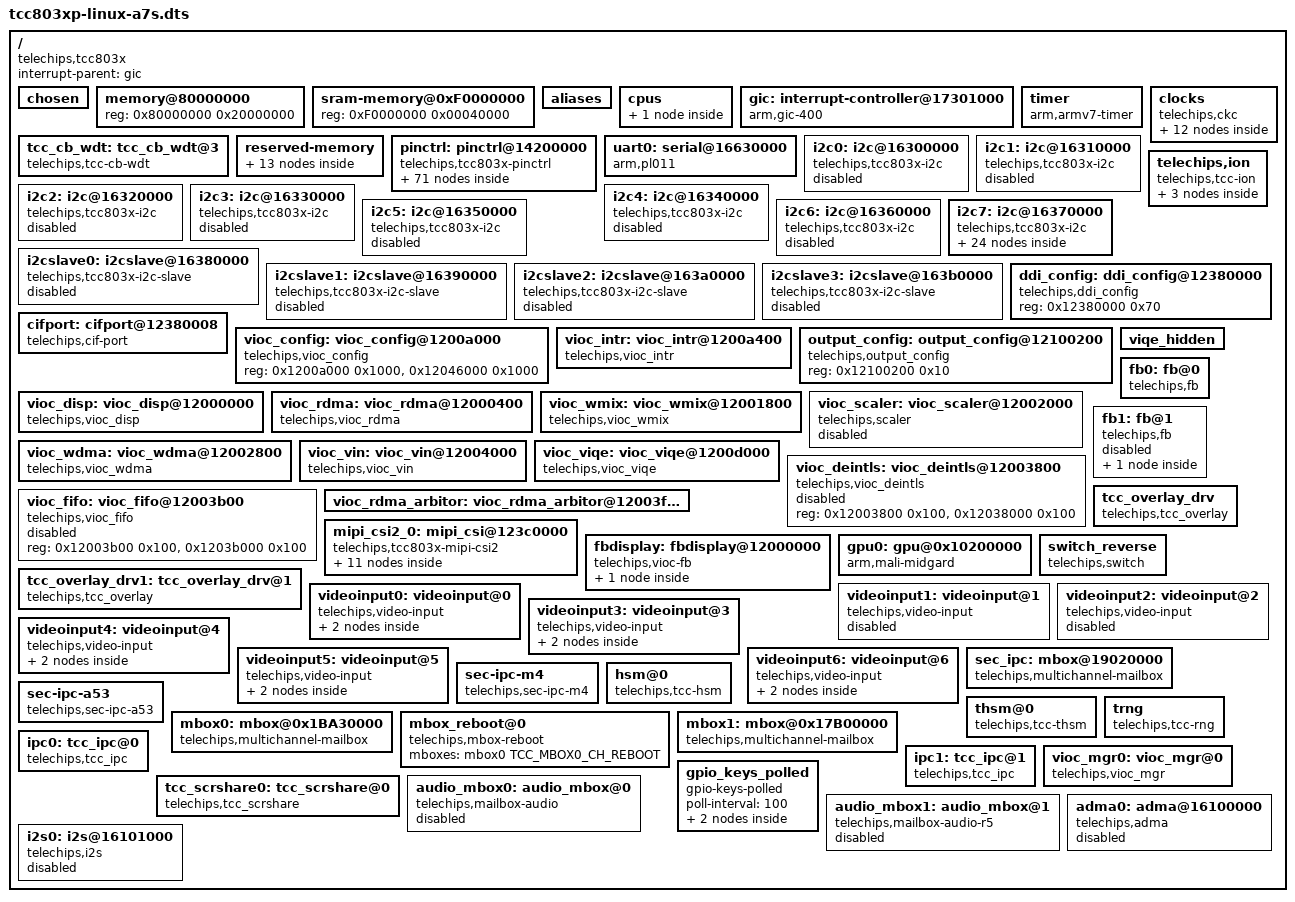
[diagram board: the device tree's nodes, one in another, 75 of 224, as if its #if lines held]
// SPDX-License-Identifier: (GPL-2.0-or-later OR MIT)
/*
 * Copyright (C) Telechips Inc.
 */

/dts-v1/;

#include <dt-bindings/interrupt-controller/arm-gic.h>
#include <dt-bindings/clock/telechips,tcc803x-clks.h>
#include <dt-bindings/display/tcc803x-vioc.h>
#include <dt-bindings/gpio/gpio.h>
#include <dt-bindings/mailbox/tcc803x_multi_mailbox/tcc_mbox_ch.h>
#include <dt-bindings/pmap/tcc803x/pmap-tcc803x-linux-ivi-subcore-a7s.h>

/ {
	compatible = "telechips,tcc803x";
	interrupt-parent = <&gic>;
	#address-cells = <1>;
	#size-cells = <1>;

	chosen {
		bootargs = "vmalloc=480M cgroup_disable=memory console=ttyAMA0,115200n8 initrd=0x87000000,22M quiet";
		stdout-path = &uart0;
	};

	memory@80000000 {
		#address-cells = <1>;
		#size-cells = <1>;
		device_type = "memory";
		reg = <0x80000000 0x20000000>;
	};

	sram-memory@0xF0000000 {
		reg = <0xF0000000 0x00040000>;
	};

	aliases {
		serial0 = &uart0;
		i2c0 = &i2c0;
		i2c1 = &i2c1;
		i2c2 = &i2c2;
		i2c3 = &i2c3;
		i2c4 = &i2c4;
		i2c5 = &i2c5;
		i2c6 = &i2c6;
		i2c7 = &i2c7;
		fb0 = &fb0;
		fb1 = &fb1;
		mipi-csi2-0 = &mipi_csi2_0;
		videoinput0 = &videoinput0;
		videoinput1 = &videoinput1;
		videoinput2 = &videoinput2;
		videoinput3 = &videoinput3;
		videoinput4 = &videoinput4;
		videoinput5 = &videoinput5;
		videoinput6 = &videoinput6;
		i2s0 = &i2s0;
		adma0 = &adma0;
#if defined(CONFIG_OVERLAY1)
		tcc-overlay-drv1 = &tcc_overlay_drv1;
#endif
	};

	cpus {
		#address-cells = <1>;
		#size-cells = <0>;

		cpu@0 {
			device_type = "cpu";
			compatible = "arm,cortex-a7";
			reg = <0x0>;
			clock-frequency = <1000000000>;
			operating-points = <
				/* kHz    uV */
				1000000  1100000
				925000   1050000
				850000   1000000
				775000   950000
				700000   900000
			>;
		};
	};

	gic: interrupt-controller@17301000 {
		compatible = "arm,gic-400";
		#interrupt-cells = <3>;
		#address-cells = <0>;
		interrupt-controller;
		reg = <0x17F01000 0x1000>,
		      <0x17F02000 0x1000>,
		      <0x17F04000 0x2000>,
		      <0x17F06000 0x2000>;
	};

	timer {
		compatible = "arm,armv7-timer";
		interrupts = <GIC_PPI 13 (GIC_CPU_MASK_SIMPLE(4) | IRQ_TYPE_LEVEL_LOW)>,
			     <GIC_PPI 14 (GIC_CPU_MASK_SIMPLE(4) | IRQ_TYPE_LEVEL_LOW)>,
			     <GIC_PPI 11 (GIC_CPU_MASK_SIMPLE(4) | IRQ_TYPE_LEVEL_LOW)>,
			     <GIC_PPI 10 (GIC_CPU_MASK_SIMPLE(4) | IRQ_TYPE_LEVEL_LOW)>;
	};

	tcc_cb_wdt: tcc_cb_wdt@3 {
		compatible = "telechips,tcc-cb-wdt";
		reg = <0x17040000 0x10000>, /* watchdog kick timer */
		    <0x17050000 0x10000>; /* real watchdog */
		clocks= <&clk_peri PERI_CB_WDT>;
		clock-frequency = <12000000>;
		interrupts = <GIC_SPI 121 0>;

		kick-interval = <5>;
		expire-timeout = <20>;

		status = "okay";
	};

	reserved-memory {
		#address-cells = <1>;
		#size-cells = <1>;
		ranges;

		/*-----------------------------------------------------------
		 * Secure Area 1 (CPU R/W, VPU X, GPU R/W, VIOC R)
		 *-----------------------------------------------------------
		 */
		pmap_fb_video: fb_video {
			compatible = "telechips,pmap";
			telechips,pmap-name = "fb_video";
			alloc-ranges = <RESERVED_MEM_BASE RESERVED_MEM_SIZE>;
			size = <PMAP_SIZE_FB_VIDEO>;
			no-map;
		};

		pmap_fb1_video: fb1_video {
			compatible = "telechips,pmap";
			telechips,pmap-name = "fb1_video";
			alloc-ranges = <RESERVED_MEM_BASE RESERVED_MEM_SIZE>;
			size = <PMAP_SIZE_FB1_VIDEO>;
			no-map;
		};

		/*-----------------------------------------------------------
		 * Secure Area 4 (CPU X, VPU X, GPU R/W, VIOC R/W)
		 *-----------------------------------------------------------
		 */
		pmap_ump_reserved: ump_reserved {
			compatible = "telechips,pmap";
			telechips,pmap-name = "ump_reserved";
			alloc-ranges = <RESERVED_MEM_BASE RESERVED_MEM_SIZE>;
			// Max-Video-Resolution(Aligned_256KB(w*h*3/2))*12+1MB
			size = <PMAP_SIZE_UMP_RESERVED>;
		};

		pmap_ion_carveout_cam: ion_carveout_cam {
			compatible = "telechips,pmap";
			telechips,pmap-name = "ion_carveout_cam";
			alloc-ranges = <RESERVED_MEM_BASE RESERVED_MEM_SIZE>;
			size = <PMAP_SIZE_ION_CARVEOUT_CAM>; // 12MB
		};

		/*-----------------------------------------------------------
		 * Camera Memory
		 *-----------------------------------------------------------
		 */
		pmap_parking_gui: parking_gui {
			compatible = "telechips,pmap";
			telechips,pmap-name = "parking_gui";
			alloc-ranges = <CAMERA_MEM_BASE CAMERA_MEM_SIZE>;
			size = <PMAP_SIZE_CAMERA_PGL>;
			no-map;
		};

		pmap_rearcamera_viqe: rearcamera_viqe {
			compatible = "telechips,pmap";
			telechips,pmap-name = "rearcamera_viqe";
			alloc-ranges = <CAMERA_MEM_BASE CAMERA_MEM_SIZE>;
			size = <PMAP_SIZE_CAMERA_VIQE>;
			no-map;
		};

		pmap_rearcamera: rearcamera {
			compatible = "telechips,pmap";
			telechips,pmap-name = "rearcamera";
			alloc-ranges = <CAMERA_MEM_BASE CAMERA_MEM_SIZE>;
			size = <PMAP_SIZE_CAMERA_PREVIEW0>;
			// no-map;
		};

		pmap_rearcamera1: rearcamera1 {
			compatible = "telechips,pmap";
			telechips,pmap-name = "rearcamera1";
			alloc-ranges = <CAMERA_MEM_BASE CAMERA_MEM_SIZE>;
			size = <PMAP_SIZE_CAMERA_PREVIEW1>;
			// no-map;
		};

		pmap_rearcamera2: rearcamera2 {
			compatible = "telechips,pmap";
			telechips,pmap-name = "rearcamera2";
			alloc-ranges = <CAMERA_MEM_BASE CAMERA_MEM_SIZE>;
			size = <PMAP_SIZE_CAMERA_PREVIEW2>;
			// no-map;
		};

		pmap_rearcamera3: rearcamera3 {
			compatible = "telechips,pmap";
			telechips,pmap-name = "rearcamera3";
			alloc-ranges = <CAMERA_MEM_BASE CAMERA_MEM_SIZE>;
			size = <PMAP_SIZE_CAMERA_PREVIEW3>;
			// no-map;
		};

		pmap_rearcamera4: rearcamera4 {
			compatible = "telechips,pmap";
			telechips,pmap-name = "rearcamera4";
			alloc-ranges = <CAMERA_MEM_BASE CAMERA_MEM_SIZE>;
			size = <PMAP_SIZE_CAMERA_PREVIEW4>;
			// no-map;
		};

		pmap_rearcamera5: rearcamera5 {
			compatible = "telechips,pmap";
			telechips,pmap-name = "rearcamera5";
			alloc-ranges = <CAMERA_MEM_BASE CAMERA_MEM_SIZE>;
			size = <PMAP_SIZE_CAMERA_PREVIEW5>;
			// no-map;
		};

		pmap_rearcamera6: rearcamera6 {
			compatible = "telechips,pmap";
			telechips,pmap-name = "rearcamera6";
			alloc-ranges = <CAMERA_MEM_BASE CAMERA_MEM_SIZE>;
			size = <PMAP_SIZE_CAMERA_PREVIEW6>;
			// no-map;
		};
	};

	clocks {
		compatible = "telechips,ckc";
		#address-cells = <1>;
		#size-cells = <1>;
		reg = <0x14000000 0x0001A8	/* ckc */
		       0x14400000 0x000114	/* pmu */
		       0x13500000 0x000018	/* memory bus configutaion */
		       0x12380000 0x000008	/* display bus configutaion */
		       0x10010000 0x000008	/* graphic bus configutaion */
		       0x16051000 0x000018	/* io bus configutaion 0 */
		       0x16494400 0x000008	/* io bus configutaion 1 */
		       0x15100000 0x200000	/* video bus configutaion */
		       0x11DA0000 0x000008	/* hsio bus configutaion */
		       0x17000000 0x300000	/* cpu bus configuration */
		       0x10000000 0x000010	/* graphic 3d clk */
		       0x1A000000 0x000010	/* graphic 2d clk */
		       0x13540000 0x000010>;	/* memory phy clk */

		osc24m: oscillator {
			compatible = "fixed-clock";
			#clock-cells = <0>;
			clock-frequency = <24000000>;
			clock-output-names = "osc24m";
		};

		clk_pll: pll_clk {
			compatible = "telechips,clk-pll";
			#clock-cells = <1>;
			clocks = <&osc24m>;
			clock-output-names = "pll0", "pll1", "pll2", "pll3",
					     "pll4";
		};

		clk_ext0: clk_ext@0 {
			compatible = "fixed-clock";
			#clock-cells = <0>;
			clock-frequency = <24000000>;
			clock-output-names = "clk_ext0";
		};

		clk_ext1: clk_ext@1 {
			compatible = "fixed-clock";
			#clock-cells = <0>;
			clock-frequency = <24000000>;
			clock-output-names = "clk_ext1";
		};

		clk_fbus: clk@14000008 {
			compatible = "telechips,clk-fbus";
			#clock-cells = <1>;
			clock-indices =
				<FBUS_CPU0>, <FBUS_CPU1>, <FBUS_CBUS>, <FBUS_CMBUS>,
				<FBUS_MEM>, <FBUS_VBUS>, <FBUS_HSIO>, <FBUS_SMU>,
				<FBUS_GPU>, <FBUS_DDI>, <FBUS_G2D>, <FBUS_IO>,
				<FBUS_CODA>, <FBUS_CHEVC>, <FBUS_BHEVC>,
				<FBUS_MEM_PHY>;
			clock-output-names =
				"fbus_cpu0", "fbus_cpu1", "fbus_cbus", "fbus_cmbus",
				"fbus_mem", "fbus_vbus", "fbus_hsio", "fbus_smu",
				"fbus_gpu", "fbus_ddi", "fbus_g2d", "fbus_io",
				"fbus_coda", "fbus_chevc", "fbus_bhevc",
				"fbus_mem_phy";
			telechips,clock-flags =
				<0>,	/* FBUS_CPU0 */
				<CLK_IGNORE_UNUSED>,	/* FBUS_CPU1 */
				<(CLK_SET_RATE_GATE | CLK_IGNORE_UNUSED)>,	/* FBUS_CBUS */
				<(CLK_SET_RATE_GATE | CLK_IGNORE_UNUSED)>,	/* FBUS_CMBUS */
				<(CLK_SET_RATE_GATE | CLK_IGNORE_UNUSED)>,	/* FBUS_MEM */
				<CLK_SET_RATE_GATE>,	/* FBUS_VBUS */
				<CLK_SET_RATE_GATE>,	/* FBUS_HSIO */
				<(CLK_SET_RATE_GATE | CLK_IGNORE_UNUSED)>,	/* FBUS_SMU */
				<0>,	/* FBUS_GPU */
				<CLK_SET_RATE_GATE>,	/* FBUS_DDI */
				<0>,	/* FBUS_G2D */
				<(CLK_SET_RATE_GATE | CLK_IS_CRITICAL)>,	/* FBUS_IO */
				<CLK_SET_RATE_GATE>,	/* FBUS_CODA */
				<CLK_SET_RATE_GATE>,	/* FBUS_CHEVC */
				<CLK_SET_RATE_GATE>,	/* FBUS_BHEVC */
				<0>;	/* FBUS_MEM_PHY */
		};

		clk_peri: clk@140000d0 {
			compatible = "telechips,clk-peri";
			#clock-cells = <1>;
			clock-indices =
				<PERI_TCX>, <PERI_TCT>, <PERI_TCZ>,
				<PERI_LCDTIMER>, <PERI_LCD0>, <PERI_LCD1>,
				<PERI_LCD2>, <PERI_CPUINTERFACE0>,
				<PERI_CPUINTERFACE1>, <PERI_HDMI_CORE>,
				<PERI_HDMI_AUDIO>, <PERI_HDMI_PCLK>,
				<PERI_HDMI_CEC>, <PERI_HDMI_HDCP14>,
				<PERI_HDMI_HDCP22>, <PERI_GMAC>,
				<PERI_PCIE_PCS>, <PERI_GMAC_PTP>,
				<PERI_PCIE_AUX>, <PERI_PCIE_REF_EXT>,
				<PERI_PCIE_APB>, <PERI_MIPI_CSI>, <PERI_RMT>,
				<PERI_SDMMC0>, <PERI_SDMMC1>, <PERI_SDMMC2>,
				<PERI_CEC1_CORE>, <PERI_MDAI0>, <PERI_MFLT0_DAI>,
				<PERI_MSPDIF0>, <PERI_SRCH0_CORE>,
				<PERI_SRCH0_FILTER>, <PERI_SRCH0_SPDIF>,
				<PERI_PDM>, <PERI_CEC1_SFR>, <PERI_TSADC>,
				<PERI_I2C0>, <PERI_I2C1>, <PERI_I2C2>, <PERI_I2C3>,
				<PERI_UART0>, <PERI_UART1>, <PERI_UART2>,
				<PERI_UART3>, <PERI_MDAI1>, <PERI_MFLT1_DAI>,
				<PERI_MSPDIF1>, <PERI_MDAI2>, <PERI_GPSB0>,
				<PERI_GPSB1>, <PERI_GPSB2>, <PERI_GPSBMS0>,
				<PERI_GPSBMS1>, <PERI_GPSBMS2>, <PERI_UART4>,
				<PERI_AUX0_INPUT>, <PERI_AUX1_INPUT>,
				<PERI_MFLT2_DAI>, <PERI_AUX0_OUTPUT>,
				<PERI_AUX1_OUTPUT>, <PERI_MSPDIF2>, <PERI_IC_TC>,
				<PERI_SRCH1_CORE>, <PERI_SRCH1_FILTER>,
				<PERI_SRCH1_SPDIF>, <PERI_SRCH2_CORE>,
				<PERI_SRCH2_FILTER>, <PERI_SRCH2_SPDIF>,
				<PERI_SRCH3_CORE>, <PERI_SRCH3_FILTER>,
				<PERI_SRCH3_SPDIF>, <PERI_TSRX0>, <PERI_TSRX1>,
				<PERI_TSRX2>, <PERI_TSRX3>, <PERI_TSRX4>,
				<PERI_TSRX5>, <PERI_TSRX6>, <PERI_TSRX7>,
				<PERI_TSRX8>, <PERI_CB_WDT>, <PERI_LVDS_PHY>,
				<PERI_OUT0>, <PERI_OUT1>, <PERI_OUT2>, <PERI_OUT3>,
				<PERI_OUT4>, <PERI_OUT5>;
			clock-output-names =
				"peri_tcx", "peri_tct", "peri_tcz",
				"peri_lcdtimer", "peri_lcd0", "peri_lcd1",
				"peri_lcd2", "peri_cpuinterface0",
				"peri_cpuinterface1", "peri_hdmi_core",
				"peri_hdmi_audio", "peri_hdmi_pclk",
				"peri_hdmi_cec", "peri_hdmi_hdcp14",
				"peri_hdmi_hdcp22", "peri_gmac",
				"peri_pcie_pcs", "peri_gmac_ptp",
				"peri_pcie_aux", "peri_pcie_ref_ext",
				"peri_pcie_apb", "peri_mipi_csi", "peri_rmt",
				"peri_sdmmc0", "peri_sdmmc1", "peri_sdmmc2",
				"peri_cec1_core", "peri_mdai0", "peri_mflt0_dai",
				"peri_mspdif0", "peri_srch0_core",
				"peri_srch0_filter", "peri_srch0_spdif",
				"peri_pdm", "peri_cec1_sfr", "peri_tsadc",
				"peri_i2c0", "peri_i2c1", "peri_i2c2", "peri_i2c3",
				"peri_uart0", "peri_uart1", "peri_uart2",
				"peri_uart3", "peri_mdai1", "peri_mflt1_dai",
				"peri_mspdif1", "peri_mdai2", "peri_gpsb0",
				"peri_gpsb1", "peri_gpsb2", "peri_gpsbms0",
				"peri_gpsbms1", "peri_gpsbms2", "peri_uart4",
				"peri_aux0_input", "peri_aux1_input",
				"peri_mflt2_dai", "peri_aux0_output",
				"peri_aux1_output", "peri_mspdif2", "peri_ic_tc",
				"peri_srch1_core", "peri_srch1_filter",
				"peri_srch1_spdif", "peri_srch2_core",
				"peri_srch2_filter", "peri_srch2_spdif",
				"peri_srch3_core", "peri_srch3_filter",
				"peri_srch3_spdif", "peri_tsrx0", "peri_tsrx1",
				"peri_tsrx2", "peri_tsrx3", "peri_tsrx4",
				"peri_tsrx5", "peri_tsrx6", "peri_tsrx7",
				"peri_tsrx8", "peri_cb_wdt", "peri_lvds_phy",
				"peri_out0", "peri_out1", "peri_out2", "peri_out3",
				"peri_out4", "peri_out5";
			telechips,clock-flags =
				<CLK_IGNORE_UNUSED>,	/* PERI_TCX */
				<CLK_IGNORE_UNUSED>,	/* PERI_TCT */
				<CLK_IGNORE_UNUSED>,	/* PERI_TCZ */
				<CLK_IGNORE_UNUSED>,	/* PERI_LCDTIMER */
				<CLK_IGNORE_UNUSED>,	/* PERI_LCD0 */
				<CLK_IGNORE_UNUSED>,	/* PERI_LCD1 */
				<CLK_IGNORE_UNUSED>,	/* PERI_LCD2 */
				<CLK_IGNORE_UNUSED>,	/* PERI_CPUINTERFACE0 */
				<CLK_IGNORE_UNUSED>,	/* PERI_CPUINTERFACE1 */
				<CLK_IGNORE_UNUSED>,	/* PERI_HDMI_CORE */
				<CLK_IGNORE_UNUSED>,	/* PERI_HDMI_AUDIO */
				<CLK_IGNORE_UNUSED>,	/* PERI_HDMI_PCLK */
				<CLK_IGNORE_UNUSED>,	/* PERI_HDMI_CEC */
				<CLK_IGNORE_UNUSED>,	/* PERI_HDMI_HDCP14 */
				<CLK_IGNORE_UNUSED>,	/* PERI_HDMI_HDCP22 */
				<CLK_IGNORE_UNUSED>,	/* PERI_GMAC */
				<CLK_IGNORE_UNUSED>,	/* PERI_PCIE_PCS */
				<CLK_IGNORE_UNUSED>,	/* PERI_GMAC_PTP */
				<CLK_IGNORE_UNUSED>,	/* PERI_PCIE_AUX */
				<CLK_IGNORE_UNUSED>,	/* PERI_PCIE_REF_EXT */
				<CLK_IGNORE_UNUSED>,	/* PERI_PCIE_APB */
				<CLK_IGNORE_UNUSED>,	/* PERI_MIPI_CSI */
				<CLK_IGNORE_UNUSED>,	/* PERI_RMT */
				<CLK_IGNORE_UNUSED>,	/* PERI_SDMMC0 */
				<CLK_IGNORE_UNUSED>,	/* PERI_SDMMC1 */
				<CLK_IGNORE_UNUSED>,	/* PERI_SDMMC2 */
				<CLK_IGNORE_UNUSED>,	/* PERI_CEC1_CORE */
				<CLK_IGNORE_UNUSED>,	/* PERI_MDAI0 */
				<CLK_IGNORE_UNUSED>,	/* PERI_MFLT0_DAI */
				<CLK_IGNORE_UNUSED>,	/* PERI_MSPDIF0 */
				<CLK_IGNORE_UNUSED>,	/* PERI_SRCH0_CORE */
				<CLK_IGNORE_UNUSED>,	/* PERI_SRCH0_FILTER */
				<CLK_IGNORE_UNUSED>,	/* PERI_SRCH0_SPDIF */
				<CLK_IGNORE_UNUSED>,	/* PERI_PDM */
				<CLK_IGNORE_UNUSED>,	/* PERI_CEC1_SFR */
				<CLK_IGNORE_UNUSED>,	/* PERI_TSADC */
				<CLK_IGNORE_UNUSED>,	/* PERI_I2C0 */
				<CLK_IGNORE_UNUSED>,	/* PERI_I2C1 */
				<CLK_IGNORE_UNUSED>,	/* PERI_I2C2 */
				<CLK_IGNORE_UNUSED>,	/* PERI_I2C3 */
				<CLK_IGNORE_UNUSED>,	/* PERI_UART0 */
				<CLK_IGNORE_UNUSED>,	/* PERI_UART1 */
				<CLK_IGNORE_UNUSED>,	/* PERI_UART2 */
				<CLK_IGNORE_UNUSED>,	/* PERI_UART3 */
				<CLK_IGNORE_UNUSED>,	/* PERI_MDAI1 */
				<CLK_IGNORE_UNUSED>,	/* PERI_MFLT1_DAI */
				<CLK_IGNORE_UNUSED>,	/* PERI_MSPDIF1 */
				<CLK_IGNORE_UNUSED>,	/* PERI_MDAI2 */
				<CLK_IGNORE_UNUSED>,	/* PERI_GPSB0 */
				<CLK_IGNORE_UNUSED>,	/* PERI_GPSB1 */
				<CLK_IGNORE_UNUSED>,	/* PERI_GPSB2 */
				<CLK_IGNORE_UNUSED>,	/* PERI_GPSBMS0 */
				<CLK_IGNORE_UNUSED>,	/* PERI_GPSBMS1 */
				<CLK_IGNORE_UNUSED>,	/* PERI_GPSBMS2 */
				<CLK_IGNORE_UNUSED>,	/* PERI_UART4 */
				<CLK_IGNORE_UNUSED>,	/* PERI_AUX0_INPUT */
				<CLK_IGNORE_UNUSED>,	/* PERI_AUX1_INPUT */
				<CLK_IGNORE_UNUSED>,	/* PERI_MFLT2_DAI */
				<CLK_IGNORE_UNUSED>,	/* PERI_AUX0_OUTPUT */
				<CLK_IGNORE_UNUSED>,	/* PERI_AUX1_OUTPUT */
				<CLK_IGNORE_UNUSED>,	/* PERI_MSPDIF2 */
				<CLK_IGNORE_UNUSED>,	/* PERI_IC_TC */
				<CLK_IGNORE_UNUSED>,	/* PERI_SRCH1_CORE */
				<CLK_IGNORE_UNUSED>,	/* PERI_SRCH1_FILTER */
				<CLK_IGNORE_UNUSED>,	/* PERI_SRCH1_SPDIF */
				<CLK_IGNORE_UNUSED>,	/* PERI_SRCH2_CORE */
				<CLK_IGNORE_UNUSED>,	/* PERI_SRCH2_FILTER */
				<CLK_IGNORE_UNUSED>,	/* PERI_SRCH2_SPDIF */
				<CLK_IGNORE_UNUSED>,	/* PERI_SRCH3_CORE */
				<CLK_IGNORE_UNUSED>,	/* PERI_SRCH3_FILTER */
				<CLK_IGNORE_UNUSED>,	/* PERI_SRCH3_SPDIF */
				<CLK_IGNORE_UNUSED>,	/* PERI_TSRX0 */
				<CLK_IGNORE_UNUSED>,	/* PERI_TSRX1 */
				<CLK_IGNORE_UNUSED>,	/* PERI_TSRX2 */
				<CLK_IGNORE_UNUSED>,	/* PERI_TSRX3 */
				<CLK_IGNORE_UNUSED>,	/* PERI_TSRX4 */
				<CLK_IGNORE_UNUSED>,	/* PERI_TSRX5 */
				<CLK_IGNORE_UNUSED>,	/* PERI_TSRX6 */
				<CLK_IGNORE_UNUSED>,	/* PERI_TSRX7 */
				<CLK_IGNORE_UNUSED>,	/* PERI_TSRX8 */
				<CLK_IGNORE_UNUSED>,	/* PERI_CB_WDT */
				<CLK_IGNORE_UNUSED>,	/* PERI_LVDS_PHY */
				<CLK_IGNORE_UNUSED>,	/* PERI_OUT0 */
				<CLK_IGNORE_UNUSED>,	/* PERI_OUT1 */
				<CLK_IGNORE_UNUSED>,	/* PERI_OUT2 */
				<CLK_IGNORE_UNUSED>,	/* PERI_OUT3 */
				<CLK_IGNORE_UNUSED>,	/* PERI_OUT4 */
				<CLK_IGNORE_UNUSED>;	/* PERI_OUT5 */
		};

		clk_io: clk@16051000 {
			compatible = "telechips,clk-iobus";
			#clock-cells = <1>;
			clocks = <&clk_fbus FBUS_IO>;
			clock-indices =
				<IOBUS_ASRC_DMA>, <IOBUS_ASRC>, <IOBUS_IC_TC>,
				<IOBUS_CEC1>, <IOBUS_DMA0>, <IOBUS_DMA1>,
				<IOBUS_DMA2>, <IOBUS_DMA>, <IOBUS_PWM>,
				<IOBUS_I2C_S2>, <IOBUS_REMOCON>, <IOBUS_PRT>,
				<IOBUS_ADMA0>, <IOBUS_DAI0>, <IOBUS_SPDIF0>,
				<IOBUS_AUDIO0>, <IOBUS_SR_ADMA0>,
				<IOBUS_SR_DAI0>, <IOBUS_SR_SPDIF0>,
				<IOBUS_SR_AUDIO0>, <IOBUS_I2C_M0>,
				<IOBUS_I2C_M1>, <IOBUS_I2C_M2>, <IOBUS_I2C_M3>,
				<IOBUS_I2C_S0>, <IOBUS_I2C_S1>, <IOBUS_I2C0>,
				<IOBUS_I2C1>, <IOBUS_GPSB_2>, <IOBUS_GPSB0>,
				<IOBUS_GPSB1>, <IOBUS_GPSB2>, <IOBUS_GPSB3>,
				<IOBUS_GPSB4>, <IOBUS_GPSB5>, <IOBUS_GPSB>,
				<IOBUS_I2C_S3>, <IOBUS_I2C_M4>, <IOBUS_I2C_M5>,
				<IOBUS_I2C_M6>, <IOBUS_I2C_M7>, <IOBUS_UART0>,
				<IOBUS_UART1>, <IOBUS_UART2>, <IOBUS_UART3>,
				<IOBUS_UART4>, <IOBUS_SMARTCARD4>, <IOBUS_UDMA0>,
				<IOBUS_UDMA1>, <IOBUS_UDMA2>, <IOBUS_UDMA3>,
				<IOBUS_UART_SMARTCARD0>,
				<IOBUS_UART_SMARTCARD1>, <IOBUS_ADMA1>, <IOBUS_DAI1>,
				<IOBUS_SPDIF1>, <IOBUS_AUDIO1>, <IOBUS_ADMA2>,
				<IOBUS_DAI2>, <IOBUS_SPDIF2>, <IOBUS_AUDIO2>,
				<IOBUS_SR_ADMA1>, <IOBUS_SR_DAI1>,
				<IOBUS_SR_SPDIF1>, <IOBUS_SR_AUDIO1>,
				<IOBUS_SR_ADMA2>, <IOBUS_SR_DAI2>,
				<IOBUS_SR_SPDIF2>, <IOBUS_SR_AUDIO2>,
				<IOBUS_SR_ADMA3>, <IOBUS_SR_DAI3>,
				<IOBUS_SR_SPDIF3>, <IOBUS_SR_AUDIO3>, <IOBUS_GDMA1>,
				<IOBUS_CIPHER>, <IOBUS_SDMMC0>, <IOBUS_SDMMC1>,
				<IOBUS_SDMMC2>, <IOBUS_SDMMC>, <IOBUS_SMC>,
				<IOBUS_NFC>, <IOBUS_EDICFG>, <IOBUS_EDI>,
				<IOBUS_RTC>;
			clock-output-names =
				"iobus_asrc_dma", "iobus_asrc", "iobus_ic_tc",
				"iobus_cec1", "iobus_dma0", "iobus_dma1",
				"iobus_dma2", "iobus_dma", "iobus_pwm",
				"iobus_i2c_s2", "iobus_remocon", "iobus_prt",
				"iobus_adma0", "iobus_dai0", "iobus_spdif0",
				"iobus_audio0", "iobus_sr_adma0",
				"iobus_sr_dai0", "iobus_sr_spdif0",
				"iobus_sr_audio0", "iobus_i2c_m0",
				"iobus_i2c_m1", "iobus_i2c_m2", "iobus_i2c_m3",
				"iobus_i2c_s0", "iobus_i2c_s1", "iobus_i2c0",
				"iobus_i2c1", "iobus_gpsb_2", "iobus_gpsb0",
				"iobus_gpsb1", "iobus_gpsb2", "iobus_gpsb3",
				"iobus_gpsb4", "iobus_gpsb5", "iobus_gpsb",
				"iobus_i2c_s3", "iobus_i2c_m4", "iobus_i2c_m5",
				"iobus_i2c_m6", "iobus_i2c_m7", "iobus_uart0",
				"iobus_uart1", "iobus_uart2", "iobus_uart3",
				"iobus_uart4", "iobus_smartcard4", "iobus_udma0",
				"iobus_udma1", "iobus_udma2", "iobus_udma3",
				"iobus_uart_smartcard0",
				"iobus_uart_smartcard1", "iobus_adma1", "iobus_dai1",
				"iobus_spdif1", "iobus_audio1", "iobus_adma2",
				"iobus_dai2", "iobus_spdif2", "iobus_audio2",
				"iobus_sr_adma1", "iobus_sr_dai1",
				"iobus_sr_spdif1", "iobus_sr_audio1",
				"iobus_sr_adma2", "iobus_sr_dai2",
				"iobus_sr_spdif2", "iobus_sr_audio2",
				"iobus_sr_adma3", "iobus_sr_dai3",
				"iobus_sr_spdif3", "iobus_sr_audio3", "iobus_gdma1",
				"iobus_cipher", "iobus_sdmmc0", "iobus_sdmmc1",
				"iobus_sdmmc2", "iobus_sdmmc", "iobus_smc",
				"iobus_nfc", "iobus_edicfg", "iobus_edi",
				"iobus_rtc";
			telechips,clock-flags =
				<CLK_IGNORE_UNUSED>,	/* IOBUS_ASRC_DMA */
				<CLK_IGNORE_UNUSED>,	/* IOBUS_ASRC */
				<CLK_IGNORE_UNUSED>,	/* IOBUS_IC_TC */
				<CLK_IGNORE_UNUSED>,	/* IOBUS_CEC1 */
				<CLK_IGNORE_UNUSED>,	/* IOBUS_DMA0 */
				<CLK_IGNORE_UNUSED>,	/* IOBUS_DMA1 */
				<CLK_IGNORE_UNUSED>,	/* IOBUS_DMA2 */
				<CLK_IGNORE_UNUSED>,	/* IOBUS_DMA */
				<CLK_IGNORE_UNUSED>,	/* IOBUS_PWM */
				<CLK_IGNORE_UNUSED>,	/* IOBUS_I2C_S2 */
				<CLK_IGNORE_UNUSED>,	/* IOBUS_REMOCON */
				<CLK_IGNORE_UNUSED>,	/* IOBUS_PRT */
				<CLK_IGNORE_UNUSED>,	/* IOBUS_ADMA0 */
				<CLK_IGNORE_UNUSED>,	/* IOBUS_DAI0 */
				<CLK_IGNORE_UNUSED>,	/* IOBUS_SPDIF0 */
				<CLK_IGNORE_UNUSED>,	/* IOBUS_AUDIO0 */
				<CLK_IGNORE_UNUSED>,	/* IOBUS_SR_ADMA0 */
				<CLK_IGNORE_UNUSED>,	/* IOBUS_SR_DAI0 */
				<CLK_IGNORE_UNUSED>,	/* IOBUS_SR_SPDIF0 */
				<CLK_IGNORE_UNUSED>,	/* IOBUS_SR_AUDIO0 */
				<CLK_IGNORE_UNUSED>,	/* IOBUS_I2C_M0 */
				<CLK_IGNORE_UNUSED>,	/* IOBUS_I2C_M1 */
				<CLK_IGNORE_UNUSED>,	/* IOBUS_I2C_M2 */
				<CLK_IGNORE_UNUSED>,	/* IOBUS_I2C_M3 */
				<CLK_IGNORE_UNUSED>,	/* IOBUS_I2C_S0 */
				<CLK_IGNORE_UNUSED>,	/* IOBUS_I2C_S1 */
				<CLK_IGNORE_UNUSED>,	/* IOBUS_I2C0 */
				<CLK_IGNORE_UNUSED>,	/* IOBUS_I2C1 */
				<CLK_IGNORE_UNUSED>,	/* IOBUS_GPSB_2 */
				<CLK_IGNORE_UNUSED>,	/* IOBUS_GPSB0 */
				<CLK_IGNORE_UNUSED>,	/* IOBUS_GPSB1 */
				<CLK_IGNORE_UNUSED>,	/* IOBUS_GPSB2 */
				<CLK_IGNORE_UNUSED>,	/* IOBUS_GPSB3 */
				<CLK_IGNORE_UNUSED>,	/* IOBUS_GPSB4 */
				<CLK_IGNORE_UNUSED>,	/* IOBUS_GPSB5 */
				<CLK_IGNORE_UNUSED>,	/* IOBUS_GPSB */
				<CLK_IGNORE_UNUSED>,	/* IOBUS_I2C_S3 */
				<CLK_IGNORE_UNUSED>,	/* IOBUS_I2C_M4 */
				<CLK_IGNORE_UNUSED>,	/* IOBUS_I2C_M5 */
				<CLK_IGNORE_UNUSED>,	/* IOBUS_I2C_M6 */
				<CLK_IGNORE_UNUSED>,	/* IOBUS_I2C_M7 */
				<CLK_IGNORE_UNUSED>,	/* IOBUS_UART0 */
				<CLK_IGNORE_UNUSED>,	/* IOBUS_UART1 */
				<CLK_IGNORE_UNUSED>,	/* IOBUS_UART2 */
				<CLK_IGNORE_UNUSED>,	/* IOBUS_UART3 */
				<CLK_IGNORE_UNUSED>,	/* IOBUS_UART4 */
				<CLK_IGNORE_UNUSED>,	/* IOBUS_SMARTCARD4 */
				<CLK_IGNORE_UNUSED>,	/* IOBUS_UDMA0 */
				<CLK_IGNORE_UNUSED>,	/* IOBUS_UDMA1 */
				<CLK_IGNORE_UNUSED>,	/* IOBUS_UDMA2 */
				<CLK_IGNORE_UNUSED>,	/* IOBUS_UDMA3 */
				<CLK_IGNORE_UNUSED>,	/* IOBUS_UART_SMARTCARD0 */
				<CLK_IGNORE_UNUSED>,	/* IOBUS_UART_SMARTCARD1 */
				<CLK_IGNORE_UNUSED>,	/* IOBUS_ADMA1 */
				<CLK_IGNORE_UNUSED>,	/* IOBUS_DAI1 */
				<CLK_IGNORE_UNUSED>,	/* IOBUS_SPDIF1 */
				<CLK_IGNORE_UNUSED>,	/* IOBUS_AUDIO1 */
				<CLK_IGNORE_UNUSED>,	/* IOBUS_ADMA2 */
				<CLK_IGNORE_UNUSED>,	/* IOBUS_DAI2 */
				<CLK_IGNORE_UNUSED>,	/* IOBUS_SPDIF2 */
				<CLK_IGNORE_UNUSED>,	/* IOBUS_AUDIO2 */
				<CLK_IGNORE_UNUSED>,	/* IOBUS_SR_ADMA1 */
				<CLK_IGNORE_UNUSED>,	/* IOBUS_SR_DAI1 */
				<CLK_IGNORE_UNUSED>,	/* IOBUS_SR_SPDIF1 */
				<CLK_IGNORE_UNUSED>,	/* IOBUS_SR_AUDIO1 */
				<CLK_IGNORE_UNUSED>,	/* IOBUS_SR_ADMA2 */
				<CLK_IGNORE_UNUSED>,	/* IOBUS_SR_DAI2 */
				<CLK_IGNORE_UNUSED>,	/* IOBUS_SR_SPDIF2 */
				<CLK_IGNORE_UNUSED>,	/* IOBUS_SR_AUDIO2 */
				<CLK_IGNORE_UNUSED>,	/* IOBUS_SR_ADMA3 */
				<CLK_IGNORE_UNUSED>,	/* IOBUS_SR_DAI3 */
				<CLK_IGNORE_UNUSED>,	/* IOBUS_SR_SPDIF3 */
				<CLK_IGNORE_UNUSED>,	/* IOBUS_SR_AUDIO3 */
				<CLK_IGNORE_UNUSED>,	/* IOBUS_GDMA1 */
				<CLK_IGNORE_UNUSED>,	/* IOBUS_CIPHER */
				<CLK_IGNORE_UNUSED>,	/* IOBUS_SDMMC0 */
				<CLK_IGNORE_UNUSED>,	/* IOBUS_SDMMC1 */
				<CLK_IGNORE_UNUSED>,	/* IOBUS_SDMMC2 */
				<CLK_IGNORE_UNUSED>,	/* IOBUS_SDMMC */
				<CLK_IGNORE_UNUSED>,	/* IOBUS_SMC */
				<CLK_IGNORE_UNUSED>,	/* IOBUS_NFC */
				<CLK_IGNORE_UNUSED>,	/* IOBUS_EDICFG */
				<CLK_IGNORE_UNUSED>,	/* IOBUS_EDI */
				<CLK_IGNORE_UNUSED>;	/* IOBUS_RTC */
		};

		clk_hsio: clk@111a0000 {
			compatible = "telechips,clk-hsiobus";
			#clock-cells = <1>;
			clocks = <&clk_fbus FBUS_HSIO>;
			clock-indices =
				<HSIOBUS_GMAC>, <HSIOBUS_HSIC>, <HSIOBUS_USB20H>,
				<HSIOBUS_CIPHER>, <HSIOBUS_USB20DH>,
				<HSIOBUS_SECURE_WRAP>, <HSIOBUS_TRNG>;
			clock-output-names =
				"hsiobus_gmac", "hsiobus_hsic", "hsiobus_usb20h",
				"hsiobus_cipher", "hsiobus_usb20dh",
				"hsiobus_secure_wrap", "hsiobus_trng";
			telechips,clock-flags =
				<CLK_IGNORE_UNUSED>,	/* HSIOBUS_GMAC */
				<CLK_IGNORE_UNUSED>,	/* HSIOBUS_HSIC */
				<CLK_IGNORE_UNUSED>,	/* HSIOBUS_USB20H */
				<CLK_IGNORE_UNUSED>,	/* HSIOBUS_CIPHER */
				<CLK_IGNORE_UNUSED>,	/* HSIOBUS_USB20DH */
				<CLK_IGNORE_UNUSED>,	/* HSIOBUS_SECURE_WRAP */
				<CLK_IGNORE_UNUSED>;	/* HSIOBUS_TRNG */
		};
		clk_ddi: clk@12380000 {
			compatible = "telechips,clk-ddibus";
			#clock-cells = <1>;
			clocks = <&clk_fbus FBUS_DDI>;
			clock-indices =
				<DDIBUS_VIOC>, <DDIBUS_HDMI>, <DDIBUS_MIPI>,
				<DDIBUS_LVDS>;
			clock-output-names =
				"ddibus_vioc", "ddibus_hdmi", "ddibus_mipi",
				"ddibus_lvds";
			telechips,clock-flags =
				<CLK_IGNORE_UNUSED>,	/* DDIBUS_VIOC */
				<CLK_IGNORE_UNUSED>,	/* DDIBUS_HDMI */
				<CLK_IGNORE_UNUSED>,	/* DDIBUS_MIPI */
				<CLK_IGNORE_UNUSED>;	/* DDIBUS_LVDS */
		};

		clk_vpu: clk@15100000 {
			compatible = "telechips,clk-vpubus";
			#clock-cells = <1>;
			clocks = <&clk_fbus FBUS_VBUS>;
			clock-indices =
				<VIDEOBUS_JPEG>, <VIDEOBUS_CODA_BUS>,
				<VIDEOBUS_CODA_CORE>, <VIDEOBUS_HEVC_BUS>,
				<VIDEOBUS_HEVC_CORE>;
			clock-output-names =
				"videobus_jpeg", "videobus_coda_bus",
				"videobus_coda_core", "videobus_hevc_bus",
				"videobus_hevc_core";
			telechips,clock-flags =
				<0>,	/* VIDEOBUS_JPEG */
				<0>,	/* VIDEOBUS_CODA_BUS */
				<0>,	/* VIDEOBUS_CODA_CORE */
				<0>,	/* VIDEOBUS_HEVC_BUS */
				<0>;	/* VIDEOBUS_HEVC_CORE */
		};

		clk_isoip_top: clk@1440007c {
			compatible = "telechips,clk-isoip_top";
			#clock-cells = <1>;
			clock-indices =
				<ISOIP_TOP_VLD>, <ISOIP_TOP_POR>,
				<ISOIP_TOP_ECID>, <ISOIP_TOP_OSC>,
				<ISOIP_TOP_ADC>, <ISOIP_TOP_RTC>,
				<ISOIP_TOP_U30>, <ISOIP_TOP_U20H>,
				<ISOIP_TOP_U20DH>, <ISOIP_TOP_PCIE>,
				<ISOIP_TOP_OTP>, <ISOIP_TOP_TSEN>,
				<ISOIP_TOP_DPLL>, <ISOIP_TOP_NPLL>,
				<ISOIP_TOP_MBPLL>, <ISOIP_TOP_DMC0>;
			clock-output-names =
				"isoip_top_vld", "isoip_top_por",
				"isoip_top_ecid", "isoip_top_osc",
				"isoip_top_adc", "isoip_top_rtc",
				"isoip_top_u30", "isoip_top_u20h",
				"isoip_top_u20dh", "isoip_top_pcie",
				"isoip_top_otp", "isoip_top_tsen",
				"isoip_top_dpll", "isoip_top_npll",
				"isoip_top_mbpll", "isoip_top_dmc0";
			telechips,clock-flags =
				<CLK_IGNORE_UNUSED>,	/* ISOIP_TOP_VLD */
				<CLK_IGNORE_UNUSED>,	/* ISOIP_TOP_POR */
				<CLK_IGNORE_UNUSED>,	/* ISOIP_TOP_ECID */
				<CLK_IGNORE_UNUSED>,	/* ISOIP_TOP_OSC */
				<CLK_IGNORE_UNUSED>,	/* ISOIP_TOP_ADC */
				<CLK_IGNORE_UNUSED>,	/* ISOIP_TOP_RTC */
				<CLK_IGNORE_UNUSED>,	/* ISOIP_TOP_U30 */
				<CLK_IGNORE_UNUSED>,	/* ISOIP_TOP_U20H */
				<CLK_IGNORE_UNUSED>,	/* ISOIP_TOP_U20DH */
				<CLK_IGNORE_UNUSED>,	/* ISOIP_TOP_PCIE */
				<CLK_IGNORE_UNUSED>,	/* ISOIP_TOP_OTP */
				<CLK_IGNORE_UNUSED>,	/* ISOIP_TOP_TSEN */
				<CLK_IGNORE_UNUSED>,	/* ISOIP_TOP_DPLL */
				<CLK_IGNORE_UNUSED>,	/* ISOIP_TOP_NPLL */
				<CLK_IGNORE_UNUSED>,	/* ISOIP_TOP_MBPLL */
				<CLK_IGNORE_UNUSED>;	/* ISOIP_TOP_DMC0 */
		};

		clk_isoip_ddi: clk@14400074 {
			compatible = "telechips,clk-isoip_ddi";
			#clock-cells = <1>;
			clock-indices =
				<ISOIP_DDB_HDMI>, <ISOIP_DDB_LVDS>,
				<ISOIP_DDB_VDAC>, <ISOIP_DDB_MIPI>;
			clock-output-names =
				"isoip_ddb_hdmi", "isoip_ddb_lvds",
				"isoip_ddb_vdac", "isoip_ddb_mipi";
			telechips,clock-flags =
				<CLK_IGNORE_UNUSED>,	/* ISOIP_DDB_HDMI */
				<CLK_IGNORE_UNUSED>,	/* ISOIP_DDB_LVDS */
				<CLK_IGNORE_UNUSED>,	/* ISOIP_DDB_VDAC */
				<CLK_IGNORE_UNUSED>;	/* ISOIP_DDB_MIPI */
		};
	};

	pinctrl: pinctrl@14200000 {
		compatible = "telechips,tcc803x-pinctrl";
		reg = <0x14200000 0x300 0x14800800 0x100>; /* gpio, pmgpio */
		gpio-controller;
		#address-cells = <1>;
		#size-cells = <0>;
		#gpio-cells = <3>;
		interrupts = <GIC_SPI 0 0>,
				   <GIC_SPI 1 0>,
				   <GIC_SPI 2 0>,
				   <GIC_SPI 3 0>,
				   <GIC_SPI 4 0>,
				   <GIC_SPI 5 0>,
				   <GIC_SPI 6 0>,
				   <GIC_SPI 7 0>,
				   <GIC_SPI 8 0>,
				   <GIC_SPI 9 0>,
				   <GIC_SPI 10 0>,
				   <GIC_SPI 11 0>,
				   <GIC_SPI 12 0>,
				   <GIC_SPI 13 0>,
				   <GIC_SPI 14 0>;
	};

	uart0: serial@16630000 {
		compatible = "arm,pl011", "arm,primecell";
		reg = <0x16630000 0x1000>;
		arm,primecell-periphid = <0x001feff7>;
		interrupts = <GIC_SPI 56 IRQ_TYPE_LEVEL_HIGH>;
		clocks = <&clk_peri PERI_UART3>, <&clk_io IOBUS_UART3>;
		clock-names = "uartclk", "apb_pclk";
		status = "disabled";
	};

	i2c0: i2c@16300000 {
		compatible = "telechips,tcc803x-i2c";
		reg = <0x16300000 0x1c 0x163c0000 0x10 0x16340004 0x04>;
		interrupts = <GIC_SPI 35 IRQ_TYPE_LEVEL_HIGH>;
		#address-cells = <1>;
		#size-cells = <0>;
		clocks = <&clk_peri PERI_I2C0 &clk_io IOBUS_I2C_M0 &clk_fbus FBUS_IO>;
		clock-frequency = <400000>;
		port-mux = <0xFF>;      /* default value */
		status = "disabled";
		interrupt_mode = <0>;
	};

	i2c1: i2c@16310000 {
		compatible = "telechips,tcc803x-i2c";
		reg = <0x16310000 0x1c 0x163c0000 0x10 0x16350004 0x04>;
		interrupts = <GIC_SPI 35 IRQ_TYPE_LEVEL_HIGH>;
		#address-cells = <1>;
		#size-cells = <0>;
		clocks = <&clk_peri PERI_I2C1 &clk_io IOBUS_I2C_M1 &clk_fbus FBUS_IO>;
		clock-frequency = <400000>;
		port-mux = <0xFF>;      /* default value */
		status = "disabled";
		interrupt_mode = <0>;
	};

	i2c2: i2c@16320000 {
		compatible = "telechips,tcc803x-i2c";
		reg = <0x16320000 0x1c 0x163c0000 0x10 0x16360004 0x04>;
		interrupts = <GIC_SPI 36 IRQ_TYPE_LEVEL_HIGH>;
		#address-cells = <1>;
		#size-cells = <0>;
		clocks = <&clk_peri PERI_I2C2 &clk_io IOBUS_I2C_M2 &clk_fbus FBUS_IO>;
		clock-frequency = <400000>;
		port-mux = <0xFF>;      /* default value */
		status = "disabled";
		interrupt_mode = <0>;
	};

	i2c3: i2c@16330000 {
		compatible = "telechips,tcc803x-i2c";
		reg = <0x16330000 0x1c 0x163c0000 0x10 0x16370004 0x04>;
		interrupts = <GIC_SPI 36 IRQ_TYPE_LEVEL_HIGH>;
		#address-cells = <1>;
		#size-cells = <0>;
		clocks = <&clk_peri PERI_I2C3 &clk_io IOBUS_I2C_M3 &clk_fbus FBUS_IO>;
		/*Set CP I2C frequency to 100Khz*/
		clock-frequency = <100000>;
		port-mux = <0xFF>;      /* default value */
		status = "disabled";
		interrupt_mode = <0>;
	};

	i2c4: i2c@16340000 {
		compatible = "telechips,tcc803x-i2c";
		reg = <0x16340000 0x1c 0x163c0000 0x10 0x16300004 0x04>;
		interrupts = <GIC_SPI 35 IRQ_TYPE_LEVEL_HIGH>;
		#address-cells = <1>;
		#size-cells = <0>;
		clocks = <&clk_peri PERI_I2C0 &clk_io IOBUS_I2C_M4 &clk_fbus FBUS_IO>;
		clock-frequency = <100000>;
		/*Set CP I2C frequency to 100Khz*/
		port-mux = <0xFF>;      /* default value */
		status = "disabled";
		interrupt_mode = <0>;
	};

	i2c5: i2c@16350000 {
		compatible = "telechips,tcc803x-i2c";
		reg = <0x16350000 0x1c 0x163c0000 0x10 0x16310004 0x04>;
		interrupts = <GIC_SPI 35 IRQ_TYPE_LEVEL_HIGH>;
		#address-cells = <1>;
		#size-cells = <0>;
		clocks = <&clk_peri PERI_I2C1 &clk_io IOBUS_I2C_M5 &clk_fbus FBUS_IO>;
		clock-frequency = <100000>;
		/*Set CP I2C frequency to 100Khz*/
		port-mux = <0xFF>;      /* default value */
		status = "disabled";
		interrupt_mode = <0>;
	};

	i2c6: i2c@16360000 {
		compatible = "telechips,tcc803x-i2c";
		reg = <0x16360000 0x1c 0x163c0000 0x10 0x16320004 0x04>;
		interrupts = <GIC_SPI 36 IRQ_TYPE_LEVEL_HIGH>;
		#address-cells = <1>;
		#size-cells = <0>;
		clocks = <&clk_peri PERI_I2C2 &clk_io IOBUS_I2C_M6 &clk_fbus FBUS_IO>;
		clock-frequency = <100000>;
		/*Set CP I2C frequency to 100Khz*/
		port-mux = <0xFF>;      /* default value */
		status = "disabled";
		interrupt_mode = <0>;
	};

	i2c7: i2c@16370000 {
		compatible = "telechips,tcc803x-i2c";
		reg = <0x16370000 0x1c 0x163c0000 0x10 0x16330004 0x04>;
		interrupts = <GIC_SPI 36 IRQ_TYPE_LEVEL_HIGH>;
		#address-cells = <1>;
		#size-cells = <0>;
		clocks = <&clk_peri PERI_I2C3 &clk_io IOBUS_I2C_M7 &clk_fbus FBUS_IO>;
		clock-frequency = <100000>;
		interrupt_mode = <0>;

		status = "okay";
		port-mux = <12>;
		pinctrl-names = "default";
		pinctrl-0 = <&i2c12_bus>;

		/* video decoder using parallel interface output */
		adv7182: adv7182 {
			status		= "okay";
			compatible	= "adi,adv7182";
			pinctrl-names	= "default";
			pinctrl-0	= <&cam0_clk &cam0_data_8bit>;
			cifport		= <0>;
			rst-gpios	= <&gpb 14 0>;
			reg		= <0x21>;	// 0x42 >> 1

			port {
				adv7182_out: endpoint {
					remote-endpoint = <&videoinput0_in>;
					io-direction	= "output";
					bus-width	= <8>;
				};
			};
		};

		/*
		 * mcnex(for ecarx demo) camera module: max96701, max9286
		 */
		ar0147: ar0147 {
			/* Camera Image Sensor */
			status		= "disabled";
			compatible	= "onnn,ar0147";
			reg		= <0x10>;
			port {
				ar0147_out: endpoint {
					remote-endpoint = <&max96701_in>;
					io-direction	= "output";
				};
			};
		};
		/* HD camera module & max9286 using MIPI CSI2 output */
		max96701: max96701 {
			/* serializer */
			status		= "okay";
			compatible	= "maxim,max96701";
			reg		= <0x40>;
			ports {
				#address-cells = <1>;
				#size-cells = <0>;
			        port@0 {
					reg = <0>;
					max96701_in: endpoint {
						//remote-endpoint = <&ar0147_out>;
						//io-direction	= "input";
					};
				};
			        port@1 {
					reg = <1>;
					max96701_out: endpoint {
						remote-endpoint = <&max9286_in0>;
						io-direction	= "output";
					};
				};
	                };
		};

		max9286: max9286 {
			/* deserializer */
			status		= "okay";
			compatible	= "maxim,max9286";
			pwd-gpios	= <&gpg 5 1>;
			intb-gpios	= <&gph 11 1>;
			//rst-gpios	= <&gpb 15 1>;  /* mcnex module sensor */
			reg		= <0x48>;	// 0x90 >> 1
			ports {
				#address-cells = <1>;
				#size-cells = <0>;
				/*
				 * 0 ~ 3
				 * input ports. The number is matched with VC
				 *
				 * 4
				 * output port.
				 */
			        port@0 {
					reg = <0>;
					max9286_in0: endpoint {
						remote-endpoint = <&max96701_out>;
						io-direction	= "input";
						channel		= <0>;
					};
				};
			        port@1 {
					reg = <1>;
					max9286_in1: endpoint {
						remote-endpoint = <&max96701_out>;
						io-direction	= "input";
						channel		= <1>;
					};
				};
			        port@2 {
					reg = <2>;
					max9286_in2: endpoint {
						remote-endpoint = <&max96701_out>;
						io-direction	= "input";
						channel		= <2>;
					};
				};
			        port@3 {
					reg = <3>;
					max9286_in3: endpoint {
						remote-endpoint = <&max96701_out>;
						io-direction	= "input";
						channel		= <3>;
					};
				};
			        port@4 {
					reg = <4>;
					max9286_out: endpoint {
						remote-endpoint = <&mipi_csi2_0_in>;
						io-direction	= "output";
					};
				};
	                };
		};
	};

	i2cslave0: i2cslave@16380000 {
		compatible = "telechips,tcc803x-i2c-slave";
		reg = <0x16380000 0x28 0x163c0000 0x10>;
		interrupts = <GIC_SPI 37 IRQ_TYPE_LEVEL_HIGH>;
		#address-cells = <1>;
		#size-cells = <0>;
		clocks = <&clk_io IOBUS_I2C_S0>;
		id = <0>;
		status = "disabled";

		/* USE DMA-engine */
		//dmas = <&dma0 0 24>, <&dma0 1 28>;
		//dma-names = "tx", "rx";
	};

	i2cslave1: i2cslave@16390000 {
		compatible = "telechips,tcc803x-i2c-slave";
		reg = <0x16390000 0x28 0x163c0000 0x10>;
		interrupts = <GIC_SPI 37 IRQ_TYPE_LEVEL_HIGH>;
		#address-cells = <1>;
		#size-cells = <0>;
		clocks = <&clk_io IOBUS_I2C_S1>;
		id = <1>;
		status = "disabled";

		/* USE DMA-engine */
		//dmas = <&dma0 0 25>, <&dma0 1 29>;
		//dma-names = "tx", "rx";
	};

	i2cslave2: i2cslave@163a0000 {
		compatible = "telechips,tcc803x-i2c-slave";
		reg = <0x163a0000 0x28 0x163c0000 0x10>;
		interrupts = <GIC_SPI 37 IRQ_TYPE_LEVEL_HIGH>;
		#address-cells = <1>;
		#size-cells = <0>;
		clocks = <&clk_io IOBUS_I2C_S2>;
		id = <2>;
		status = "disabled";

		/* USE DMA-engine */
		//dmas = <&dma0 0 26>, <&dma0 1 30>;
		//dma-names = "tx", "rx";
	};

	i2cslave3: i2cslave@163b0000 {
		compatible = "telechips,tcc803x-i2c-slave";
		reg = <0x163b0000 0x28 0x163c0000 0x10>;
		interrupts = <GIC_SPI 37 IRQ_TYPE_LEVEL_HIGH>;
		#address-cells = <1>;
		#size-cells = <0>;
		clocks = <&clk_io IOBUS_I2C_S3>;
		id = <3>;
		status = "disabled";

		/* USE DMA-engine */
		//dmas = <&dma0 0 25>, <&dma0 1 29>;
		//dma-names = "tx", "rx";
	};

/*
 * Display Bus Block
 */
	telechips,ion {
		compatible = "telechips,tcc-ion";
		#address-cells = <1>;
		#size-cells = <0>;

		ion-heap@0 {
			reg = <0>;
			telechips,ion-heap-name = "ion_noncontig_heap";
		};

		ion-heap@1 {
			reg = <1>;
			telechips,ion-heap-name = "ion_contig_heap";
		};

		ion-heap@2 {
			reg = <2>;
			telechips,ion-heap-name = "ion_carveout_heap";
		};
	};

	ddi_config: ddi_config@12380000 {
		compatible = "telechips,ddi_config";
		reg = <0x12380000 0x70>;
	};

	cifport: cifport@12380008 {
		compatible = "telechips,cif-port";
		reg = <0x12380008 0x4>;
		statue = "okay";
	};

	vioc_config: vioc_config@1200a000 {
		compatible = "telechips,vioc_config";
		reg = <0x1200a000 0x1000>,
			/* VIOC_REMAP */
			  <0x12046000 0x1000>;
	};

	vioc_intr: vioc_intr@1200a400 {
		compatible = "telechips,vioc_intr";
		reg = <0x1200a400 0x100>,
			/* VIOC_REMAP */
			  <0x12046400 0x100>,
			/* For FB Core Reset, backup register (TIMER) */
				<0x1200c014 0xc>,
			/* For FB Core Reset  VIOC_REMAP */
				<0x1204A014 0xc>;
		interrupts = <GIC_SPI 84 IRQ_TYPE_LEVEL_HIGH>;
	};

	output_config: output_config@12100200 {
		compatible = "telechips,output_config";
		reg = <0x12100200 0x10>;
	};

	vioc_disp: vioc_disp@12000000 {
		compatible = "telechips,vioc_disp";
		reg = <0x12000000 0x100 0x12000100 0x100 0x12000200 0x100>,
			/* VIOC_REMAP */
			  <0x12000000 0x100 0x12001000 0x100 0x12002000 0x100>;
		interrupts = <GIC_SPI 84 IRQ_TYPE_LEVEL_HIGH>,
					 <GIC_SPI 84 IRQ_TYPE_LEVEL_HIGH>,
					 <GIC_SPI 84 IRQ_TYPE_LEVEL_HIGH>;
		clocks = <&clk_ddi DDIBUS_VIOC>,
				 <&clk_peri PERI_LCD0>,
				 <&clk_peri PERI_LCD1>,
				 <&clk_peri PERI_LCD2>;
		clock-names = "ddi-clk", "disp0-clk", "disp1-clk", "disp2-clk";
	};

	vioc_rdma: vioc_rdma@12000400{
		compatible = "telechips,vioc_rdma";
		reg = <0x12000400 0x100 0x12000500 0x100 0x12000600 0x100 0x12000700 0x100
		       0x12000800 0x100 0x12000900 0x100 0x12000a00 0x100 0x12000b00 0x100
		       0x12000c00 0x100 0x12000d00 0x100 0x12000e00 0x100 0x12000f00 0x100
		       0x12001000 0x100 0x12001100 0x100 0x12001200 0x100 0x12001300 0x100
		       0x12001400 0x100 0x12001500 0x100>,
		      /* VIOC_REMAP */
		      <0x12004000 0x100 0x12005000 0x100 0x12006000 0x100 0x12007000 0x100
		       0x12008000 0x100 0x12009000 0x100 0x1200a000 0x100 0x1200b000 0x100
		       0x1200c000 0x100 0x1200d000 0x100 0x1200e000 0x100 0x1200f000 0x100
		       0x12010000 0x100 0x12011000 0x100 0x12012000 0x100 0x12013000 0x100
		       0x12014000 0x100 0x12015000 0x100>;
		interrupts = <GIC_SPI 84 IRQ_TYPE_LEVEL_HIGH>,
			     <GIC_SPI 84 IRQ_TYPE_LEVEL_HIGH>,
			     <GIC_SPI 84 IRQ_TYPE_LEVEL_HIGH>,
			     <GIC_SPI 84 IRQ_TYPE_LEVEL_HIGH>,
			     <GIC_SPI 84 IRQ_TYPE_LEVEL_HIGH>,
			     <GIC_SPI 84 IRQ_TYPE_LEVEL_HIGH>,
			     <GIC_SPI 84 IRQ_TYPE_LEVEL_HIGH>,
			     <GIC_SPI 84 IRQ_TYPE_LEVEL_HIGH>,
			     <GIC_SPI 84 IRQ_TYPE_LEVEL_HIGH>,
			     <GIC_SPI 84 IRQ_TYPE_LEVEL_HIGH>,
			     <GIC_SPI 84 IRQ_TYPE_LEVEL_HIGH>,
			     <GIC_SPI 84 IRQ_TYPE_LEVEL_HIGH>,
			     <GIC_SPI 84 IRQ_TYPE_LEVEL_HIGH>,
			     <GIC_SPI 84 IRQ_TYPE_LEVEL_HIGH>,
			     <GIC_SPI 84 IRQ_TYPE_LEVEL_HIGH>,
			     <GIC_SPI 84 IRQ_TYPE_LEVEL_HIGH>,
			     <GIC_SPI 84 IRQ_TYPE_LEVEL_HIGH>,
			     <GIC_SPI 84 IRQ_TYPE_LEVEL_HIGH>;
	};

	vioc_wmix: vioc_wmix@12001800{
		compatible = "telechips,vioc_wmix";
		reg = <0x12001800 0x100 0x12001900 0x100 0x12001a00 0x100 0x12001b00 0x100
		       0x12001c00 0x100 0x12001d00 0x100 0x12001e00 0x100>,
		      /* VIOC_REMAP */
		      <0x12018000 0x100 0x12019000 0x100 0x1201a000 0x100 0x1201b000 0x100
		       0x1201c000 0x100 0x1201d000 0x100 0x1201e000 0x100>;
		interrupts = <GIC_SPI 84 IRQ_TYPE_LEVEL_HIGH>,
			     <GIC_SPI 84 IRQ_TYPE_LEVEL_HIGH>,
			     <GIC_SPI 84 IRQ_TYPE_LEVEL_HIGH>,
			     <GIC_SPI 84 IRQ_TYPE_LEVEL_HIGH>,
			     <GIC_SPI 84 IRQ_TYPE_LEVEL_HIGH>,
			     <GIC_SPI 84 IRQ_TYPE_LEVEL_HIGH>,
			     <GIC_SPI 84 IRQ_TYPE_LEVEL_HIGH>;
	};

	vioc_scaler:vioc_scaler@12002000{
		compatible = "telechips,scaler";
		reg = <0x12002000 0x100 0x12002100 0x100 0x12002200 0x100 0x12002300 0x100
		       0x12002400 0x100 0x12002500 0x100 0x12002600 0x100 0x12002700 0x100>,
		      /* VIOC_REMAP */
		      <0x12020000 0x100 0x12021000 0x100 0x12022000 0x100 0x12023000 0x100
		       0x12024000 0x100 0x12025000 0x100 0x12026000 0x100 0x12027000 0x100>;
		status = "disabled";
	};

	vioc_wdma:vioc_wdma@12002800{
		compatible = "telechips,vioc_wdma";
		reg = <0x12002800 0x100 0x12002900 0x100 0x12002a00 0x100 0x12002b00 0x100
		       0x12002c00 0x100 0x12002d00 0x100 0x12002e00 0x100 0x12002f00 0x100
		       0x12003000 0x100 0x12014000 0x100 0x12014100 0x100 0x12014200 0x100>,
		      /* VIOC_REMAP */
		      <0x12028000 0x100 0x12029000 0x100 0x1202a000 0x100 0x1202b000 0x100
		       0x1202c000 0x100 0x1202d000 0x100 0x1202e000 0x100 0x1202f000 0x100
		       0x12030000 0x100 0x12052000 0x100 0x12053000 0x100 0x12054000 0x100>;
		interrupts = <GIC_SPI 84 IRQ_TYPE_LEVEL_HIGH>,
			     <GIC_SPI 84 IRQ_TYPE_LEVEL_HIGH>,
			     <GIC_SPI 84 IRQ_TYPE_LEVEL_HIGH>,
			     <GIC_SPI 84 IRQ_TYPE_LEVEL_HIGH>,
			     <GIC_SPI 84 IRQ_TYPE_LEVEL_HIGH>,
			     <GIC_SPI 84 IRQ_TYPE_LEVEL_HIGH>,
			     <GIC_SPI 84 IRQ_TYPE_LEVEL_HIGH>,
			     <GIC_SPI 84 IRQ_TYPE_LEVEL_HIGH>,
			     <GIC_SPI 84 IRQ_TYPE_LEVEL_HIGH>,
			     <GIC_SPI 84 IRQ_TYPE_LEVEL_HIGH>,
			     <GIC_SPI 84 IRQ_TYPE_LEVEL_HIGH>,
			     <GIC_SPI 84 IRQ_TYPE_LEVEL_HIGH>;
	};

	vioc_vin:vioc_vin@12004000{
		compatible = "telechips,vioc_vin";
		reg = <0x12004000 0x400 0x12004400 0x600
		       0x12005000 0x400 0x12005400 0x600
		       0x12006000 0x400 0x12006400 0x600
		       0x12007000 0x400 0x12007400 0x600
		       0x12018000 0x400 0x12018400 0x600
		       0x12019000 0x400 0x12019400 0x600
		       0x1201a000 0x400 0x1201a400 0x600>,
		      /* VIOC_REMAP */
		      <0x12040000 0x400 0x12040400 0x600
		       0x12041000 0x400 0x12041400 0x600
		       0x12042000 0x400 0x12042400 0x600
		       0x12043000 0x400 0x12043400 0x600
		       0x12055000 0x400 0x12055400 0x600
		       0x12056000 0x400 0x12056400 0x600
		       0x12057000 0x400 0x12057400 0x600>;
		interrupts = <GIC_SPI 84 IRQ_TYPE_LEVEL_HIGH>,
			     <GIC_SPI 84 IRQ_TYPE_LEVEL_HIGH>,
			     <GIC_SPI 84 IRQ_TYPE_LEVEL_HIGH>,
			     <GIC_SPI 84 IRQ_TYPE_LEVEL_HIGH>,
			     <GIC_SPI 84 IRQ_TYPE_LEVEL_HIGH>,
			     <GIC_SPI 84 IRQ_TYPE_LEVEL_HIGH>,
			     <GIC_SPI 84 IRQ_TYPE_LEVEL_HIGH>,
			     <GIC_SPI 84 IRQ_TYPE_LEVEL_HIGH>,
			     <GIC_SPI 84 IRQ_TYPE_LEVEL_HIGH>,
			     <GIC_SPI 84 IRQ_TYPE_LEVEL_HIGH>,
			     <GIC_SPI 84 IRQ_TYPE_LEVEL_HIGH>,
			     <GIC_SPI 84 IRQ_TYPE_LEVEL_HIGH>,
			     <GIC_SPI 84 IRQ_TYPE_LEVEL_HIGH>,
			     <GIC_SPI 84 IRQ_TYPE_LEVEL_HIGH>,
			     <GIC_SPI 84 IRQ_TYPE_LEVEL_HIGH>;
	};

	vioc_viqe:vioc_viqe@1200d000{
		compatible = "telechips,vioc_viqe";
		reg = <0x1200d000 0x1000 0x12010000 0x1000>,
		      /* VIOC_REMAP */
		      <0x1204b000 0x1000 0x1204e000 0x1000>;
	};

	viqe_hidden:viqe_hidden{
		reg = <0x1200d100 0x4 0x1200d10c 0x4>,
		      /* VIOC_REMAP */
		      <0x1204b100 0x4 0x1204b10c 0x4>;
	};

	vioc_deintls:vioc_deintls@12003800{
		compatible = "telechips,vioc_deintls";
		reg = <0x12003800 0x100>,
		      /* VIOC_REMAP */
		      <0x12038000 0x100>;
		status = "disabled";
	};

	vioc_fifo:vioc_fifo@12003b00{
		compatible = "telechips,vioc_fifo";
		reg = <0x12003b00 0x100>,
		      /* VIOC_REMAP */
		      <0x1203b000 0x100>;
		status = "disabled";
	};

	vioc_rdma_arbitor:vioc_rdma_arbitor@12003f00{
		reg = <0x12003f00 0x20 0x12003f20 0x20 0x12003f40 0x20 0x12003f60 0x20>,
		      /* VIOC_REMAP */
		      <0x1203f000 0x20 0x1203f020 0x20 0x1203f040 0x20 0x1203f060 0x20>;
		arbitor_num = <4>;
	};

	mipi_csi2_0:mipi_csi@123c0000 {
		compatible = "telechips,tcc803x-mipi-csi2";

		status = "okay";

		reg = <0x123c0000 0x120>,
		      <0x123c0200 0x5c>;
		reg-names = "csi", "gdb";

		clocks = <&clk_peri PERI_MIPI_CSI>;
		clock-names = "mipi-csi-clk";

		clock-frequency = <300000000>;

		interrupts = <GIC_SPI 124 IRQ_TYPE_LEVEL_HIGH>,// MIPI0 CSIS
		             <GIC_SPI 125 IRQ_TYPE_LEVEL_HIGH>;// MIPI0 Generic

		ports {
			/*
			 * 0 ~ 3
			 * input port.
			 *
			 * 4
			 * output ports. The number is matched with VC
			 */
			port@0 {
				reg = <0>;
				mipi_csi2_0_in: endpoint {
					remote-endpoint	= <&max9286_out>;
					io-direction	= "input";
					num-channel = <4>;

					/*
					 * 0: CH0 only, no data interleave
					 * 1: DT only
					 * 2: VC only
					 * 3: VC and DT
					 */
					interleave-mode = <3>;
					//hs-settle = <2>;
					hs-settle = <17>;
					data-lanes = <1 2 3 4>;
				};
			};

		        port@1 {
				reg = <1>;
		                mipi_csi2_0_out0: endpoint {
		                        remote-endpoint = <&videoinput3_in>;
					io-direction	= "output";
					channel		= <0>;
					/*
					 * 0: Single pixel mode
					 * 1: Dual pixel mode (RAW8/10/12, YUV422)
					 * 2: Quad pixel mode (RAW8/10/12)
					 * 3: Invalid
					 */
					pixel-mode = <1>;
		                };
			};
			port@2 {
				reg = <2>;
				mipi_csi2_0_out1: endpoint {
					remote-endpoint	= <&videoinput4_in>;
					io-direction	= "output";
					channel		= <1>;
					pixel-mode = <1>;
				};
			};
			port@3 {
				reg = <3>;
				mipi_csi2_0_out2: endpoint {
					remote-endpoint	= <&videoinput5_in>;
					io-direction	= "output";
					channel		= <2>;
					pixel-mode = <1>;

				};
			};
			port@4 {
				reg = <4>;
				mipi_csi2_0_out3: endpoint {
					remote-endpoint	= <&videoinput6_in>;
					io-direction	= "output";
					channel		= <3>;
					pixel-mode = <1>;
				};
			};
		};
	};

	fbdisplay: fbdisplay@12000000 {
		compatible = "telechips,vioc-fb";
		reg = <0x12000000 0x10000>;
		telechips,fbdisplay_num = <0>;
		telechips,rdma_arbitor=<&vioc_rdma_arbitor>;
		memory-region = <&pmap_fb_video>;

		fbdisplay0:fbdisplay0@12000000{
			telechips,disp = <&vioc_disp VIOC_DISP0>;
			telechips,wmixer = <&vioc_wmix VIOC_WMIX0>;
			telechips,rdma = <&vioc_rdma VIOC_RDMA00 VIOC_RDMA01 VIOC_RDMA02 VIOC_RDMA03>;
			telechips,wdma = <&vioc_wdma VIOC_WDMA00>;
		};
	};

	gpu0: gpu@0x10200000 {
		compatible = "arm,mali-midgard";
		status = "okay";
		reg = <0x10200000 0x4000>;
		interrupts = <GIC_SPI 93 IRQ_TYPE_LEVEL_HIGH>,
			     <GIC_SPI 93 IRQ_TYPE_LEVEL_HIGH>,
			     <GIC_SPI 93 IRQ_TYPE_LEVEL_HIGH>;
		interrupt-names = "JOB", "MMU", "GPU";
		clocks = <&clk_fbus FBUS_GPU>;
		clock-names = "mali_clk";
	};

	fb0: fb@0 {
		compatible = "telechips,fb";
		status = "okay";
		memory-region = <&pmap_fb_video>;
		xres = <1920>;
		yres = <720>;
		bpp = <32>;
		mode = <FBX_TRIPLE>;
		update-type = <FBX_OVERLAY_UPDATE>;
		device-priority = <FBX_DEVICE_LVDS>;
		telechips,disp = <&vioc_disp VIOC_DISP0 VIOC_DISP1>;
		telechips,wmixer = <&vioc_wmix VIOC_WMIX0 VIOC_WMIX1>;
		telechips,rdma = <&vioc_rdma VIOC_RDMA01 VIOC_RDMA04>;
	};

	fb1: fb@1 {
		compatible = "telechips,fb";
		status = "disabled";
		memory-region = <&pmap_fb1_video>;
		xres = <1280>;
		yres = <720>;
		bpp = <32>;
		mode = <FBX_TRIPLE>;
		update-type = <FBX_OVERLAY_UPDATE>;
		device-priority = <FBX_DEVICE_LVDS>;
		telechips,disp = <&vioc_disp VIOC_DISP0>;
		telechips,wmixer = <&vioc_wmix VIOC_WMIX0>;
		telechips,rdma = <&vioc_rdma VIOC_RDMA02>;
		fbx_region {
			x = <0>;
			y = <0>;
			width = <1280>;
			height = <720>;
		};
	};

	tcc_overlay_drv {
		compatible = "telechips,tcc_overlay";
		fbdisplay-overlay = <&fbdisplay>;
		rdmas = <&vioc_rdma
			 VIOC_RDMA00 VIOC_RDMA01 VIOC_RDMA02 VIOC_RDMA03
			 VIOC_RDMA04 VIOC_RDMA05 VIOC_RDMA06 VIOC_RDMA07>;
		wmixs = <&vioc_wmix VIOC_WMIX0 VIOC_WMIX1>;
		rdma_init_layer = <1>;
		status = "okay";
	};

#if defined(CONFIG_OVERLAY1)
	tcc_overlay_drv1: tcc_overlay_drv@1 { //for scrshare
		compatible = "telechips,tcc_overlay";
		display_num = <0>;
		rdmas = <&vioc_rdma VIOC_RDMA00 VIOC_RDMA01 VIOC_RDMA02 VIOC_RDMA03 VIOC_RDMA04 VIOC_RDMA05 VIOC_RDMA06 VIOC_RDMA07>;
		wmixs = <&vioc_wmix VIOC_WMIX0 VIOC_WMIX1>;
		rdma_init_layer = <2>;
		status = "okay";
	};
#endif
	switch_reverse {
		compatible = "telechips,switch";
		status = "okay";

		pinctrl-names = "default";
		pinctrl-0 = <&switch_c13>;

		switch-gpios = <&gpc 13 1>;
		switch-active = <0>;
	};

	videoinput0: videoinput@0 {
		status		= "okay";
		compatible	= "telechips,video-input";
		cifport		= <&cifport 0>;
		clocks		= <&clk_ddi DDIBUS_VIOC>;
		rdma		= <&vioc_rdma VIOC_RDMA16>;
		use_pgl		= <0>;
		vin		= <&vioc_vin VIOC_VIN00>;
		viqe		= <&vioc_viqe VIOC_VIQE1>;
		viqe_set   	= <&viqe_hidden>;
		deintls		= <&vioc_deintls VIOC_DEINTLS0>;
		scaler		= <&vioc_scaler VIOC_SCALER2>;
		wmixer		= <&vioc_wmix VIOC_WMIX5>;
		wdma		= <&vioc_wdma VIOC_WDMA05>;
		fifo		= <&vioc_fifo VIOC_FIFO0>;

		port {
			videoinput0_in: endpoint {
				remote-endpoint	= <&adv7182_out>;
				io-direction	= "input";
                	        bus-type	= <0>;
				bus-with	= <8>;
				stream-enable	= <0>;	// VIN_CTRL.SE
				flush-vsync	= <0>;	// VIN_MISC.FVS
			};
		};
	};

	videoinput1: videoinput@1 {
		status		= "disabled";
		compatible	= "telechips,video-input";
		cifport		= <&cifport 1>;
		clocks		= <&clk_ddi DDIBUS_VIOC>;
		rdma		= <&vioc_rdma VIOC_RDMA17>;
		use_pgl		= <0>;
		vin		= <&vioc_vin VIOC_VIN10>;
		viqe		= <&vioc_viqe VIOC_VIQE1>;
		viqe_set   	= <&viqe_hidden>;
		deintls		= <&vioc_deintls VIOC_DEINTLS0>;
		scaler		= <&vioc_scaler VIOC_SCALER4>;
		wmixer		= <&vioc_wmix VIOC_WMIX6>;
		wdma		= <&vioc_wdma VIOC_WDMA07>;
		fifo		= <&vioc_fifo VIOC_FIFO0>;
	};

	videoinput2: videoinput@2 {
		status		= "disabled";
		compatible	= "telechips,video-input";
		cifport		= <&cifport 2>;
		clocks		= <&clk_ddi DDIBUS_VIOC>;
		rdma		= <&vioc_rdma VIOC_RDMA13>;
		use_pgl		= <0>;
		vin		= <&vioc_vin VIOC_VIN20>;
		viqe		= <&vioc_viqe VIOC_VIQE1>;
		viqe_set   	= <&viqe_hidden>;
		deintls		= <&vioc_deintls VIOC_DEINTLS0>;
		scaler		= <&vioc_scaler VIOC_SCALER5>;
		wmixer		= <&vioc_wmix VIOC_WMIX3>;
		wdma		= <&vioc_wdma VIOC_WDMA03>;
		fifo		= <&vioc_fifo VIOC_FIFO0>;
	};

	videoinput3: videoinput@3 {
		status		= "okay";
		compatible	= "telechips,video-input";
		cifport		= <&cifport 5>;
		clocks		= <&clk_ddi DDIBUS_VIOC>;
		rdma		= <&vioc_rdma VIOC_RDMA15>;
		use_pgl		= <0>;
		vin		= <&vioc_vin VIOC_VIN30>;
		viqe		= <&vioc_viqe VIOC_VIQE1>;
		viqe_set   	= <&viqe_hidden>;
		deintls		= <&vioc_deintls VIOC_DEINTLS0>;
		scaler		= <&vioc_scaler VIOC_SCALER6>;
		wmixer		= <&vioc_wmix VIOC_WMIX4>;
		wdma		= <&vioc_wdma VIOC_WDMA04>;
		fifo		= <&vioc_fifo VIOC_FIFO0>;

		port {
			videoinput3_in: endpoint {
				remote-endpoint	= <&mipi_csi2_0_out0>;
				io-direction	= "input";
				bus-type	= <0>;
				bus-with	= <8>;
				stream-enable	= <1>;	// VIN_CTRL.SE
				flush-vsync	= <1>;	// VIN_MISC.FVS
			};
		};
	};

	videoinput4: videoinput@4 {
		status		= "okay";
		compatible	= "telechips,video-input";
		cifport		= <&cifport 6>;
		clocks		= <&clk_ddi DDIBUS_VIOC>;
		use_pgl		= <0>;
		vin		= <&vioc_vin		VIOC_VIN40>;
		wdma		= <&vioc_wdma		VIOC_WDMA09>;

		port {
			videoinput4_in: endpoint {
				remote-endpoint	= <&mipi_csi2_0_out1>;
				io-direction	= "input";
				bus-type	= <0>;
				bus-with	= <8>;
				stream-enable	= <1>;	// VIN_CTRL.SE
				flush-vsync	= <1>;	// VIN_MISC.FVS
			};
		};
	};

	videoinput5: videoinput@5 {
		status		= "okay";
		compatible	= "telechips,video-input";
		cifport		= <&cifport 7>;
		clocks		= <&clk_ddi DDIBUS_VIOC>;
		use_pgl		= <0>;
		vin		= <&vioc_vin		VIOC_VIN50>;
		wdma		= <&vioc_wdma		VIOC_WDMA10>;

		port {
			videoinput5_in: endpoint {
				remote-endpoint	= <&mipi_csi2_0_out2>;
				io-direction	= "input";
				bus-type	= <0>;
				bus-with	= <8>;
				stream-enable	= <1>;	// VIN_CTRL.SE
				flush-vsync	= <1>;	// VIN_MISC.FVS
			};
		};
	};

	videoinput6: videoinput@6 {
		status		= "okay";
		compatible	= "telechips,video-input";
		cifport		= <&cifport 8>;
		clocks		= <&clk_ddi DDIBUS_VIOC>;
		use_pgl		= <0>;
		vin		= <&vioc_vin		VIOC_VIN60>;
		wdma		= <&vioc_wdma		VIOC_WDMA11>;

		port {
			videoinput6_in: endpoint {
				remote-endpoint	= <&mipi_csi2_0_out3>;
				io-direction	= "input";
				bus-type	= <0>;
				bus-with	= <8>;
				stream-enable	= <1>;	// VIN_CTRL.SE
				flush-vsync	= <1>;	// VIN_MISC.FVS
			};
		};
	};

	sec_ipc: mbox@19020000 {
		compatible = "telechips,multichannel-mailbox";
		reg = <0x19020000 0x100>;
		interrupts = <GIC_SPI 26 IRQ_TYPE_LEVEL_HIGH>;
		#mbox-cells = <1>;
		max-channel = <1>;
	};

	sec-ipc-m4 {
		compatible = "telechips,sec-ipc-m4";
		mbox-names = "sec-ipc-m4";
		mboxes = <&sec_ipc 0>;
	};

	sec-ipc-a53 {
		compatible = "telechips,sec-ipc-a53";
		mbox-names = "sec-ipc-a53";
		mboxes = <&mbox1 TCC_MBOX1_CH_HSM>;
	};

	hsm@0 {
		compatible = "telechips,tcc-hsm";
		status = "okay";
	};

	thsm@0 {
		compatible = "telechips,tcc-thsm";
		status = "okay";
	};

	trng: trng {
		compatible = "telechips,tcc-rng";
		status = "okay";
	};

	/* A7S <-> R5 */
	mbox0: mbox@0x1BA30000 {
		compatible = "telechips,multichannel-mailbox";
		reg = <0x1BA30000 0x100>;
		interrupts = <GIC_SPI 115 IRQ_TYPE_LEVEL_HIGH>;
		#mbox-cells = <1>;
		max-channel = <TCC_MBOX0_CH_MAX>;
	};

	/* ipc for reboot by r5(micom) */
	mbox_reboot@0 {
		 compatible = "telechips,mbox-reboot";
		 mboxes = <&mbox0 TCC_MBOX0_CH_REBOOT>;
	};

	/* A7S <-> A53 */
	mbox1: mbox@0x17B00000 {
		compatible = "telechips,multichannel-mailbox";
		reg = <0x17B00000 0x100>;
		interrupts = <GIC_SPI 125 IRQ_TYPE_LEVEL_HIGH>;
		#mbox-cells = <1>;
		max-channel = <TCC_MBOX1_CH_MAX>;
	};

	/* ipc for r5(micom) */
	ipc0: tcc_ipc@0 {
		 compatible = "telechips,tcc_ipc";
		 device-name = "tcc_ipc_micom";
		 mbox-names ="micom-ipc";
		 mboxes = <&mbox0 TCC_MBOX0_CH_IPC>;
	 };

	/* ipc for A7S */
	ipc1: tcc_ipc@1 {
		 compatible = "telechips,tcc_ipc";
		 device-name = "tcc_ipc_ap";
		 mbox-names ="ap-ipc";
		 mboxes = <&mbox1 TCC_MBOX1_CH_IPC>;
	 };

	/* tcc_scrshare for A7S */
	tcc_scrshare0: tcc_scrshare@0 {
		compatible = "telechips,tcc_scrshare";
		device-name ="tcc_scrshare_a7s";
		mbox-names ="a7s-scrshare";
		mboxes = <&mbox1 TCC_MBOX1_CH_SCRSHARE>;
		status = "okay";
	};

	/* vioc_mgr for A7S */
	vioc_mgr0: vioc_mgr@0 {
		compatible  = "telechips,vioc_mgr";
		device-name = "vioc_mgr_sub";
		mbox-names  = "sub-vioc";
		mboxes      = <&mbox1 TCC_MBOX1_CH_VIOC>;
		status      = "okay";
	};

	gpio_keys_polled {
		compatible = "gpio-keys-polled";
		#address-cells = <1>;
		#size-cells = <0>;
		poll-interval = <100>;
		//autorepeat;
		button@0 {
			label = "Door Key";
			linux,code = <105>;
			gpios = <&gpa 20 0>;
		};
		button@1 {
			label = "Camera Key";
			linux,code = <212>;
			gpios = <&gpma 15 1>;
		};
	};

	/* audio_mailbox (TSND) for A7S */
	audio_mbox0: audio_mbox@0 {
		compatible = "telechips,mailbox-audio";
		device-name ="audio-mbox-dev-a7s";
		mbox-names ="audio-mbox-a7s";
		mboxes = <&mbox1 TCC_MBOX1_CH_SND>;
		status = "disabled";
	};

	/* audio_mailbox (TSND) for R5 */
	audio_mbox1: audio_mbox@1 {
		compatible = "telechips,mailbox-audio-r5";
		device-name ="audio-mbox-dev-r5";
		mbox-names ="audio-mbox-r5";
		mboxes = <&mbox0 TCC_MBOX0_CH_SND>;
		status = "disabled";
	};

	adma0: adma@16100000 {
		compatible = "telechips,adma";
		reg = <0x16100000 0x200>;
		clocks = <&clk_io IOBUS_ADMA0>;
		interrupts = <GIC_SPI 47 IRQ_TYPE_LEVEL_HIGH>;
		have-hopcnt-clear = <1>;
		adrcnt-mode = <1>;
		status = "disabled";
	};

	i2s0: i2s@16101000 {
		compatible = "telechips,i2s";
		reg = <0x16101000 0x50>;
		clocks = <&clk_peri PERI_MDAI0
			  &clk_io IOBUS_DAI0
			  &clk_peri PERI_MFLT0_DAI>;
		clock-frequency = <11289600>;	// 44100*256
		have-fifo-clear=<1>;
		block-type = <1>; // 0: Stereo 1: 7.1CH
		adma = <&adma0>;
		status = "disabled";
	};
};

&pinctrl {
	gpa: gpa {
		gpio-controller;
		#gpio-cells = <2>;
		reg = <0x0 0 32>;
		source-num = <1 0 1 32>;
	};

	gpb: gpb {
		gpio-controller;
		#gpio-cells = <2>;
		reg = <0x40 0 29>;
		source-num = <1 0 33 29>;
	};

	gpc: gpc {
		gpio-controller;
		#gpio-cells = <2>;
		reg = <0x80 0 30>;
		source-num = <1 0 62 30>;
	};

	gpd: gpd {
		gpio-controller;
		#gpio-cells = <2>;
		reg = <0xc0 0 22>;
		source-num = <0xff>;
	};

	gpe: gpe {
		gpio-controller;
		#gpio-cells = <2>;
		reg = <0x100 0 20>;
		source-num = <1 0 92 20>;
	};

	gpf: gpf {
		gpio-controller;
		#gpio-cells = <2>;
		reg = <0x140 0 32>;
		source-num = <0xff>;
	};

	gpg: gpg {
		gpio-controller;
		#gpio-cells = <2>;
		reg = <0x180 0 11>;
		source-num = <1 0 112 11>;
	};

	gph: gph {
		gpio-controller;
		#gpio-cells = <2>;
		reg = <0x640 0 12>;
		source-num = <1 0 123 12>;
	};

	gpk: gpk {
		gpio-controller;
		#gpio-cells = <2>;
		reg = <0x680 0 19>;
		source-num = <0xff>;
	};

	gpma: gpma {
		gpio-controller;
		#gpio-cells = <2>;
		reg = <0x6C0 0 30>;
		source-num = <1 0 145 30>;
	};

	gpsd0: gpsd0 {
		gpio-controller;
		#gpio-cells = <2>;
		reg = <0x200 0 15>;
		source-num = <1 0 166 15>;
	};

	gpsd1: gpsd1 {
		gpio-controller;
		#gpio-cells = <2>;
		reg = <0x240 0 11>;
		source-num = <1 0 181 11>;
	};

	gpsd2: gpsd2 {
		gpio-controller;
		#gpio-cells = <2>;
		reg = <0x600 0 10>;
		source-num = <1 0 192 10>;
	};

	uart28_data: uart28_data {
		telechips,pins = "gph-4", "gph-5";
		telechips,pin-function = <7>;
	};

	i2c0_bus: i2c0_bus {
		telechips,pins = "gpsd1-4", "gpsd1-5";
		telechips,pin-function = <8>;
		telechips,input_buffer_enable;
	};

	i2c0_bus: i2c0_bus {
		telechips,pins = "gpsd1-4", "gpsd1-5";
		telechips,pin-function = <8>;
		telechips,input_buffer_enable;
	};

	i2c1_bus: i2c1_bus {
		telechips,pins = "gpsd2-2", "gpsd2-3";
		telechips,pin-function = <8>;
		telechips,input_buffer_enable;
	};

	i2c2_bus: i2c2_bus {
		telechips,pins = "gpsd2-4", "gpsd2-5";
		telechips,pin-function = <8>;
		telechips,input_buffer_enable;
	};

	i2c3_bus: i2c3_bus {
		telechips,pins = "gpa-4", "gpa-5";
		telechips,pin-function = <8>;
		telechips,input_buffer_enable;
	};

	i2c4_bus: i2c4_bus {
		telechips,pins = "gpa-10", "gpa-11";
		telechips,pin-function = <8>;
		telechips,input_buffer_enable;
	};

	i2c5_bus: i2c5_bus {
		telechips,pins = "gpa-16", "gpa-17";
		telechips,pin-function = <8>;
		telechips,input_buffer_enable;
	};

	i2c6_bus: i2c6_bus {
		telechips,pins = "gpa-22", "gpa-23";
		telechips,pin-function = <8>;
		telechips,input_buffer_enable;
	};

	i2c7_bus: i2c7_bus {
		telechips,pins = "gpa-28", "gpa-29";
		telechips,pin-function = <8>;
		telechips,input_buffer_enable;
	};

	i2c8_bus: i2c8_bus {
		telechips,pins = "gpb-4", "gpb-5";
		telechips,pin-function = <8>;
		telechips,input_buffer_enable;
	};

	i2c9_bus: i2c9_bus {
		telechips,pins = "gpb-10", "gpb-11";
		telechips,pin-function = <8>;
		telechips,input_buffer_enable;
	};

	i2c10_bus: i2c10_bus {
		telechips,pins = "gpb-17", "gpb-18";
		telechips,pin-function = <8>;
		telechips,input_buffer_enable;
	};

	i2c11_bus: i2c11_bus {
		telechips,pins = "gpb-19", "gpb-20";
		telechips,pin-function = <8>;
		telechips,input_buffer_enable;
	};

	i2c12_bus: i2c12_bus {
		telechips,pins = "gpb-21", "gpb-22";
		telechips,pin-function = <8>;
		telechips,input_buffer_enable;
	};

	i2c13_bus: i2c13_bus {
		telechips,pins = "gpb-23", "gpb-24";
		telechips,pin-function = <8>;
		telechips,input_buffer_enable;
	};

	i2c14_bus: i2c14_bus {
		telechips,pins = "gpc-14", "gpc-15";
		telechips,pin-function = <8>;
		telechips,input_buffer_enable;
	};

	i2c15_bus: i2c15_bus {
		telechips,pins = "gpc-20", "gpc-21";
		telechips,pin-function = <8>;
		telechips,input_buffer_enable;
	};

	i2c16_bus: i2c16_bus {
		telechips,pins = "gpc-24", "gpc-25";
		telechips,pin-function = <8>;
		telechips,input_buffer_enable;
	};

	i2c17_bus: i2c17_bus {
		telechips,pins = "gpc-28", "gpc-29";
		telechips,pin-function = <8>;
		telechips,input_buffer_enable;
	};

	i2c18_bus: i2c18_bus {
		telechips,pins = "gpg-4", "gpg-5";
		telechips,pin-function = <8>;
		telechips,input_buffer_enable;
	};

	i2c19_bus: i2c19_bus {
		telechips,pins = "gpe-3", "gpe-4";
		telechips,pin-function = <8>;
		telechips,input_buffer_enable;
	};

	i2c20_bus:i2c20_bus {
		telechips,pins = "gpe-9", "gpe-10";
		telechips,pin-function = <8>;
		telechips,input_buffer_enable;
	};

	i2c21_bus: i2c21_bus {
		telechips,pins = "gpe-14", "gpe-15";
		telechips,pin-function = <8>;
		telechips,input_buffer_enable;
	};

	i2c22_bus: i2c22_bus {
		telechips,pins = "gph-4", "gph-5";
		telechips,pin-function = <9>;
		telechips,input_buffer_enable;
	};

	i2c23_bus: i2c23_bus {
		telechips,pins = "gph-6", "gph-7";
		telechips,pin-function = <9>;
		telechips,input_buffer_enable;
	};

	i2c24_bus: i2c24_bus {
		telechips,pins = "gpma-4", "gpma-5";
		telechips,pin-function = <8>;
		telechips,input_buffer_enable;
	};

	i2c25_bus: i2c25_bus {
		telechips,pins = "gpma-10", "gpma-11";
		telechips,pin-function = <8>;
		telechips,input_buffer_enable;
	};

	i2c26_bus: i2c26_bus {
		telechips,pins = "gpma-16", "gpma-17";
		telechips,pin-function = <8>;
		telechips,input_buffer_enable;
	};

	i2c27_bus: i2c27_bus {
		telechips,pins = "gpma-22", "gpma-23";
		telechips,pin-function = <8>;
		telechips,input_buffer_enable;
	};

	i2c28_bus: i2c28_bus {
		telechips,pins = "gpma-28", "gpma-29";
		telechips,pin-function = <8>;
		telechips,input_buffer_enable;
	};

	switch_c13: switch_c13 {
		telechips,pins = "gpc-13";
		telechips,pin-function = <0>;
		telechips,input-enable;
		telechips,input_buffer_enable;
		telechips,no-pull;
	};

	cam0_8bit_idle: cam0_8bit_idle {
		telechips,pins = "gpa-0",
				 "gpa-3",  "gpa-4",  "gpa-5",  "gpa-6",
				 "gpa-7",  "gpa-8",  "gpa-9",  "gpa-10";
		telechips,pin-function = <0>;
		telechips,output-low;
	};

	cam0_16bit_idle: cam0_16bit_idle {
		telechips,pins = "gpa-0",
				 "gpa-3",  "gpa-4",  "gpa-5",  "gpa-6",
				 "gpa-7",  "gpa-8",  "gpa-9",  "gpa-10",
				 "gpa-13", "gpa-14", "gpa-15", "gpa-16",
				 "gpa-17", "gpa-18", "gpa-19", "gpa-20";
		telechips,pin-function = <0>;
		telechips,output-low;
	};

	cam0_clk: cam0_clk {
		telechips,pins = "gpa-0";
		telechips,pin-function = <3>;
		telechips,drive-strength = <3>;
	};

	cam0_data_8bit: cam0_data_8bit {
		telechips,pins = "gpa-3",  "gpa-4",  "gpa-5",  "gpa-6",
				 "gpa-7",  "gpa-8",  "gpa-9",  "gpa-10";
		telechips,pin-function = <3>;
		telechips,drive-strength = <3>;
	};

	cam0_data_16bit: cam0_data_16bit {
		telechips,pins = "gpa-3",  "gpa-4",  "gpa-5",  "gpa-6",
				 "gpa-7",  "gpa-8",  "gpa-9",  "gpa-10",
				 "gpa-13", "gpa-14", "gpa-15", "gpa-16",
				 "gpa-17", "gpa-18", "gpa-19", "gpa-20";
		telechips,pin-function = <3>;
		telechips,drive-strength = <3>;
	};

	/******************************************************
	 * Multi DAI Port_3 m1:multi, dai3:port3
	 ******************************************************/
	//t_SND for move sound card from a53 to a7
	m1dai3_mclk: m1dai3_mclk{
		telechips,pins = "gpe-0";
		telechips,pin-function = <1>;
	};

	m1dai3_mclk_idle: m1dai3_mclk_idle{
		telechips,pins = "gpe-0";
		telechips,pin-function = <0>;
		telechips,output-low = <0>;
	};

	m1dai3_bclk: m1dai3_bclk{
		telechips,pins = "gpe-1";
		telechips,pin-function = <1>;
	};

	m1dai3_bclk_idle: m1dai3_bclk_idle{
		telechips,pins = "gpe-1";
		telechips,pin-function = <0>;
		telechips,output-low = <0>;
	};

	m1dai3_lrck: m1dai3_lrck{
		telechips,pins = "gpe-2";
		telechips,pin-function = <1>;
	};

	m1dai3_lrck_idle: m1dai3_lrck_idle{
		telechips,pins = "gpe-2";
		telechips,pin-function = <0>;
		telechips,output-low = <0>;
	};

	m1dai3_dao0: m1dai3_dao0{
		telechips,pins = "gpe-3";
		telechips,pin-function = <1>;
	};

	m1dai3_dao0_idle: m1dai3_dao0_idle{
		telechips,pins = "gpe-3";
		telechips,pin-function = <0>;
		telechips,output-low = <0>;
	};

	m1dai3_dai0: m1dai3_dai0{
		telechips,pins = "gpe-4";
		telechips,pin-function = <1>;
	};

	m1dai3_dai0_idle: m1dai3_dai0_idle{
		telechips,pins = "gpe-4";
		telechips,pin-function = <0>;
		telechips,output-low = <0>;
	};

	m1dai3_dao1: m1dai3_dao1{
		telechips,pins = "gpe-5";
		telechips,pin-function = <1>;
	};

	m1dai3_dao1_idle: m1dai3_dao1_idle{
		telechips,pins = "gpe-5";
		telechips,pin-function = <0>;
		telechips,output-low = <0>;
	};

	m1dai3_dai1: m1dai3_dai1{
		telechips,pins = "gpe-6";
		telechips,pin-function = <1>;
	};

	m1dai3_dai1_idle: m1dai3_dai1_idle{
		telechips,pins = "gpe-6";
		telechips,pin-function = <0>;
		telechips,output-low = <0>;
	};

	m1dai3_dao2: m1dai3_dao2{
		telechips,pins = "gpe-7";
		telechips,pin-function = <1>;
	};

	m1dai3_dao2_idle: m1dai3_dao2_idle{
		telechips,pins = "gpe-7";
		telechips,pin-function = <0>;
		telechips,output-low = <0>;
	};

	m1dai3_dai2: m1dai3_dai2{
		telechips,pins = "gpe-8";
		telechips,pin-function = <1>;
	};

	m1dai3_dai2_idle: m1dai3_dai2_idle{
		telechips,pins = "gpe-8";
		telechips,pin-function = <0>;
		telechips,output-low = <0>;
	};

	m1dai3_dao3: m1dai3_dao3{
		telechips,pins = "gpe-9";
		telechips,pin-function = <1>;
	};

	m1dai3_dao3_idle: m1dai3_dao3_idle{
		telechips,pins = "gpe-9";
		telechips,pin-function = <0>;
		telechips,output-low = <0>;
	};

	m1dai3_dai3: m1dai3_dai3{
		telechips,pins = "gpe-10";
		telechips,pin-function = <1>;
	};

	m1dai3_dai3_idle: m1dai3_dai3_idle{
		telechips,pins = "gpe-10";
		telechips,pin-function = <0>;
		telechips,output-low = <0>;
	};
};

&uart0 {
	pinctrl-names = "default";
	pinctrl-0 = <&uart28_data>;
	status = "okay";
};
